VERSION ""

NS_ :

BS_:

BU_: Vector__XXX Vector__XXX ABS ACU ADAS AFS AMP APSB APSM BAT BCM BMS CCM CLU DATC DVRS Drv EPB ESC FR IAU IBU ICSC ICU IEB IFS LDC MCU MDPS MFSW OBC ODS PSM PTGM RR RVM SAS SCM SVM TMU TPMS VCMS VCU WHL YRS
CM_ "FrameID: 0xC7";
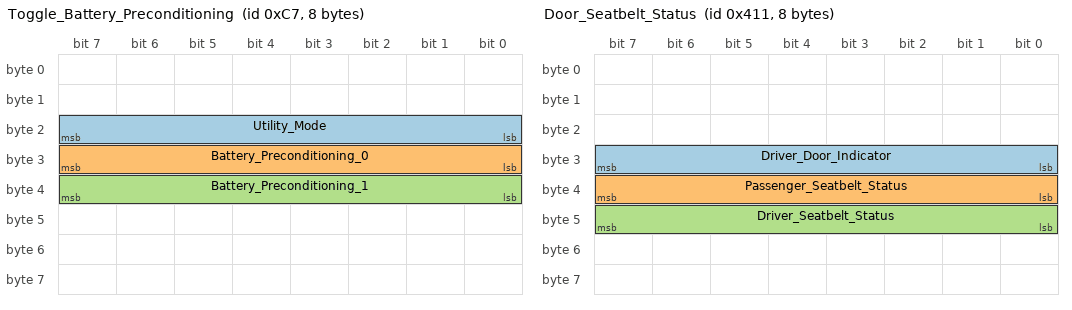
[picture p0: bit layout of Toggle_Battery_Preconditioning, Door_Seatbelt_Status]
BO_ 199 Toggle_Battery_Preconditioning: 8 Vector__XXX
 SG_ Utility_Mode              : 16|8@1+ (1,0) [0|255] "" Vector__XXX
 SG_ Battery_Preconditioning_0 : 24|8@1+ (1,0) [0|255] "" Vector__XXX
 SG_ Battery_Preconditioning_1 : 32|8@1+ (1,0) [0|255] "" Vector__XXX

CM_ "FrameID: 411";
BO_ 1041 Door_Seatbelt_Status: 8 Vector__XXX
 SG_ Driver_Door_Indicator      : 24|8@1+ (1,0) [0|255] "" Vector__XXX
 SG_ Passenger_Seatbelt_Status  : 32|8@1+ (1,0) [0|255] "" Vector__XXX
 SG_ Driver_Seatbelt_Status     : 40|8@1+ (1,0) [0|255] "" Vector__XXX
CM_ BO_ 1041 "a.k.a. ICU ICU_02_200ms in gen5w_hu_rx.dbc";
CM_ SG_ 1041 Driver_Door_Indicator "byte 3. Raw values are 0x51 = 81 (open), 0x50 = 80 (closed) and 0x00 = locked. The VAL_ keys used to be written as the decimal forms of those hex bytes (51/50), which never occur in a capture; they are now the correct integers 81/80. Bit 24 alone is the open flag (see the bit-level Body_Status in ev6-2024.dbc). The two seatbelt signals below are 8-bit wide and therefore also pick up neighbouring bits of bytes 4/5 (0x04 and 0x14 appear), so treat a set bit 36 / 42 as the seatbelt rather than the whole byte.";

CM_ "FrameID: 412";
BO_ 1042 Brake_Pedal_Status: 8 Vector__XXX
 SG_ Brake_Pedal : 48|8@1+ (1,0) [0|255] "" Vector__XXX
CM_ BO_ 1042 "a.k.a. ICU ICU_03_200ms in gen5w_hu_rx.dbc";

CM_ "FrameID: 435";
BO_ 1077 Power_CAN_Status: 8 Vector__XXX
 SG_ Power_State : 56|8@1+ (1,0) [0|255] "" Vector__XXX

CM_ "FrameID: 0x2AD";
BO_ 685 BMS_Precond_Status: 8 Vector__XXX
 SG_ Battery_Precond_State : 8|8@1+ (1,0) [0|255] "" Vector__XXX
CM_ BO_ 685 "a.k.a. VCU VCU_04_100ms_3 in gen5w_hu_rx.dbc";

CM_ "FrameID: 0x418";
BO_ 1048 Steering_Wheel_Heating: 8 Vector__XXX
 SG_ Steering_Wheel_Heating_State : 24|1@1+ (1,0) [0|1] "" Vector__XXX
CM_ BO_ 1048 "a.k.a. ICU ICU_08_200ms in gen5w_hu_rx.dbc";
CM_ SG_ 1048 Steering_Wheel_Heating_State "byte 3 bit 0. Previously modelled at 16|8 (byte 2), which is 0x00 in 100% of every capture on every car (Ioniq 5 5731, Ioniq 6 1916, GV60 1063 frames), so it could only ever read Off. Byte 3 bit 0 is the only bit that tracks the steering-wheel warmer: 0x01 in M-CAN_steering_wheel_warmer_only.csv (10/20 frames), M-CAN_panda_nothing_on_climate_start_both_warmers.csv (60/202) and M-CAN_panda_nothing_on_remote_lock.csv (16/100), and 0x00 in every other capture - including the dedicated left/right seat warmer, climate-on, climate-on-defrost and rear-defrost files, so it is not a generic warmer flag. Byte 5 bit 6 (0x0C -> 0x4C, i.e. bit 45) is the generic one: it turns on with ANY warmer and is a separate candidate signal. The steering-wheel captures are only a few seconds long, so whether byte 3 bit 0 is a latched state or the press event itself is not settled.";
CM_ SG_ 1048 Steering_Wheel_Heating_State "DIFFERENCE ON CCU CARS. This bit-0 encoding is only demonstrated on the Ioniq 5 (NE, ICU CAN hub), and likely works for the EV6 as well. The CCU-hub cars do NOT show it: every Ioniq 6 (1916 frames) and GV60 (1063 frames) sample has byte 3 = 0x40, i.e. bit 6 SET and bit 0 CLEAR, so bit 0 would decode a permanent Off there and the state - if it is reported at all - is carried elsewhere in the byte. Do not apply this signal to a CCU-hub capture (load ioniq6-2024.dbc / gv60-2024.dbc for those).";

CM_ "FrameID: 0x438";
BO_ 1080 RearLeft_Seat_Heating: 8 Vector__XXX
 SG_ RearLeft_Seat_Heating_State :  0|8@1+ (1,0) [0|255] "" Vector__XXX

CM_ "FrameID: 0x448";
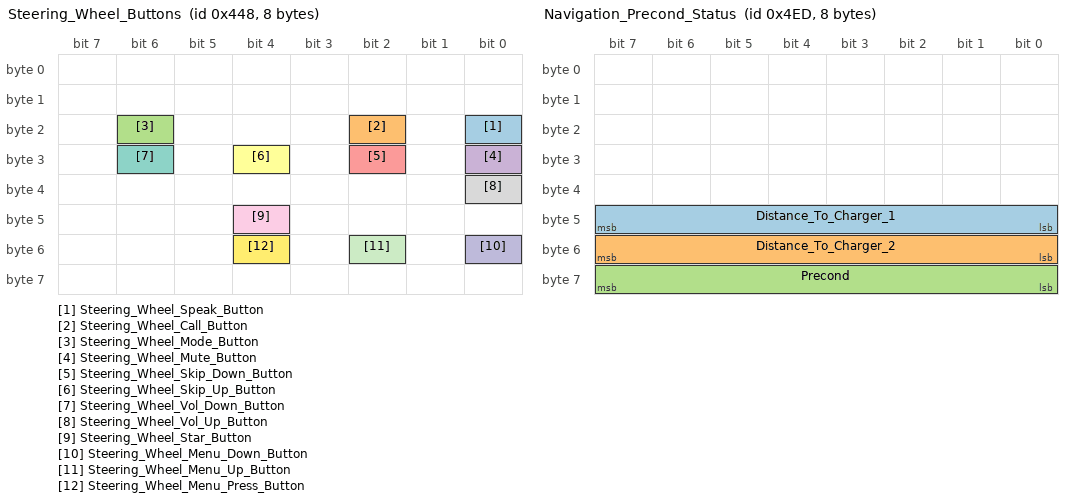
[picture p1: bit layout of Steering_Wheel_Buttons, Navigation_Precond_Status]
BO_ 1096 Steering_Wheel_Buttons: 8 Vector__XXX
 SG_ Steering_Wheel_Speak_Button      : 16|1@1+ (1,0) [0|1] "" Vector__XXX
 SG_ Steering_Wheel_Call_Button       : 18|1@1+ (1,0) [0|1] "" Vector__XXX
 SG_ Steering_Wheel_Mode_Button       : 22|1@1+ (1,0) [0|1] "" Vector__XXX
 SG_ Steering_Wheel_Mute_Button       : 24|1@1+ (1,0) [0|1] "" Vector__XXX
 SG_ Steering_Wheel_Skip_Down_Button  : 26|1@1+ (1,0) [0|1] "" Vector__XXX
 SG_ Steering_Wheel_Skip_Up_Button    : 28|1@1+ (1,0) [0|1] "" Vector__XXX
 SG_ Steering_Wheel_Vol_Down_Button   : 30|1@1+ (1,0) [0|1] "" Vector__XXX
 SG_ Steering_Wheel_Vol_Up_Button     : 32|1@1+ (1,0) [0|1] "" Vector__XXX
 SG_ Steering_Wheel_Star_Button       : 44|1@1+ (1,0) [0|1] "" Vector__XXX
 SG_ Steering_Wheel_Menu_Down_Button  : 48|1@1+ (1,0) [0|1] "" Vector__XXX
 SG_ Steering_Wheel_Menu_Up_Button    : 50|1@1+ (1,0) [0|1] "" Vector__XXX
 SG_ Steering_Wheel_Menu_Press_Button : 52|1@1+ (1,0) [0|1] "" Vector__XXX

CM_ "FrameID: 0x453";
BO_ 1107 RearRight_Seat_Heating: 8 Vector__XXX
 SG_ RearRight_Seat_Heating_State : 0|8@1+ (1,0) [0|255] "" Vector__XXX

CM_ "FrameID: 0x475";
BO_ 1141 Passenger_Seat_Heating: 8 Vector__XXX
 SG_ Passenger_Seat_Heating_State : 0|8@1+ (1,0) [0|255] "" Vector__XXX

CM_ "FrameID: 0x496";
BO_ 1174 Driver_Seat_Heating: 8 Vector__XXX
 SG_ Driver_Seat_Heating_State :    0|8@1+ (1,0) [0|255] "" Vector__XXX
CM_ BO_ 1174 "a.k.a. Drv Drv_SHVU_01_200ms in gen5w_hu_rx.dbc";

CM_ "FrameID: 0x4ED";
BO_ 1261 Navigation_Precond_Status: 8 Vector__XXX
 SG_ Distance_To_Charger_1 : 40|8@1+ (1,0) [0|255] "" Vector__XXX
 SG_ Distance_To_Charger_2 : 48|8@1+ (1,0) [0|255] "" Vector__XXX
 SG_ Precond               : 56|8@1+ (1,0) [0|255] "" Vector__XXX

CM_ "FrameID: 0x0A2";
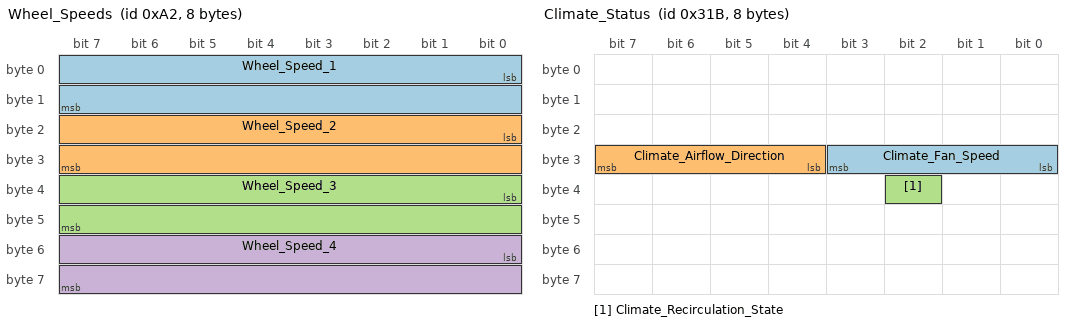
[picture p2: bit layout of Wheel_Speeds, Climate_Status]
BO_ 162 Wheel_Speeds: 8 Vector__XXX
 SG_ Wheel_Speed_1 : 0|16@1+  (0.03125,0) [0|2047.96] "kph" Vector__XXX
 SG_ Wheel_Speed_2 : 16|16@1+ (0.03125,0) [0|2047.96] "kph" Vector__XXX
 SG_ Wheel_Speed_3 : 32|16@1+ (0.03125,0) [0|2047.96] "kph" Vector__XXX
 SG_ Wheel_Speed_4 : 48|16@1+ (0.03125,0) [0|2047.96] "kph" Vector__XXX
CM_ BO_ 162 "a.k.a. WHL WHL_01_10ms_2 in gen5w_hu_rx.dbc";

CM_ "FrameID: 0x1AC";
BO_ 428 Cluster_Info: 8 Vector__XXX
 SG_ Speed_kph : 0|8@1+ (1,0) [0|255] "kph" Vector__XXX
CM_ BO_ 428 "a.k.a. CLU CLU_01_20ms_2 in gen5w_hu_rx.dbc";

CM_ "FrameID: 0x226";
CM_ "Probably wrong: unsigned int, and this byte doesn't change in my logs. --TRH";
BO_ 550 Ambient_Temperature: 8 Vector__XXX
 SG_ Outdoor_Temperature : 24|8@1+ (1,-40) [-40|215] "C" Vector__XXX
CM_ BO_ 550 "a.k.a. CLU CLU_02_100ms_1 in gen5w_hu_rx.dbc";
CM_ SG_ 550 Outdoor_Temperature "byte 3. The bit placement matches the official CLU_OutTempCSta (24|8@1+ (1,-40) [-40|215]) in BO_ 549 CLU_02_100ms of dbcs/dbcs/HMVS4_CAN-FD_DBC_3Gen_R3_rev2.dbc:178, whose VAL_ makes 0..100 = -40..60 C, 101..254 = Reserved and 255 = Invalid. Every Ioniq 5 capture on disk (old/ and current folders, M-CAN and I-CAN) reads 0xFF = 255 = Invalid in this byte, so the -40 offset reports a nonsense 215 C unless 255 is treated as no-data. Bytes 4-7 carry session-stable values of unknown meaning, so a real ambient value may live there instead; unresolved.";
VAL_ 550 Outdoor_Temperature 255 "Invalid" ;

CM_ "FrameID: 0x227";
BO_ 551 Odometer: 8 Vector__XXX
 SG_ Odometer : 8|24@1+ (0.1,0) [0|1677721] "km" Vector__XXX
CM_ BO_ 551 "a.k.a. CLU CLU_02_100ms_2 in gen5w_hu_rx.dbc";

CM_ "FrameID: 0x2FC";
BO_ 764 Battery_Info: 8 Vector__XXX
 SG_ State_Of_Charge : 56|8@1+ (0.5,0) [0|100] "%" Vector__XXX
CM_ BO_ 764 "a.k.a. BMS BMS_02_100ms_2 in gen5w_hu_rx.dbc";

CM_ "FrameID: 0x31B";
BO_ 795 Climate_Status: 8 Vector__XXX
 SG_ Climate_Fan_Speed          : 24|4@1+ (1,0) [0|15] "" Vector__XXX
 SG_ Climate_Airflow_Direction  : 28|4@1+ (1,0) [0|15] "" Vector__XXX
 SG_ Climate_Recirculation_State : 34|1@1+ (1,0) [0|1]  "" Vector__XXX
CM_ BO_ 795 "a.k.a. DATC DATC_31_1000ms_1 in gen5w_hu_rx.dbc";

CM_ BO_ 896 "First three bytes are a rolling counter (byte 0/1 non-monotonic, byte 2 increments with temp step).";
CM_ BO_ 896 "Bytes 0-1 do not appear to be a rolling counter on NA cars: they stay constant per transmitting node/state (3A 85 = HVAC running, AD D7 = HVAC off, A8 33 / C4 50 / 38 B7 / EB F0 / 75 11 / 31 04 = other nodes and transition states), and byte 2 is 00, 01 or FF. Raw 0 is the off state (AD D7 FF 00 00 00 00 01), not a 14 C setpoint. Measured 2026-10/11 on M-CAN and the I-CAN tap: 0x380 adopts a setpoint 1.7 s AFTER byte 1 of 0x39B (D2) carries the same code, with byte 4 of 0x2AC (D5) relaying it on the car bus in between.";
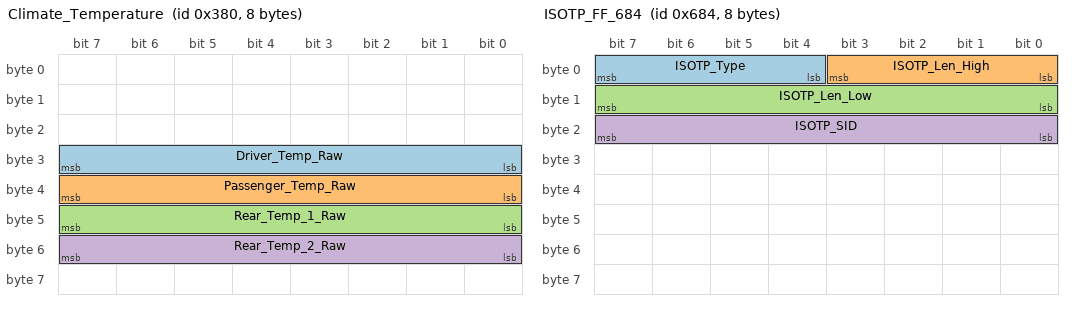
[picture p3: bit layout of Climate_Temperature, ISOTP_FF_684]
BO_ 896 Climate_Temperature: 8 Vector__XXX
 SG_ Driver_Temp_Raw    : 24|8@1+ (0.5,14) [14|32] "C" Vector__XXX
 SG_ Passenger_Temp_Raw : 32|8@1+ (0.5,14) [14|32] "C" Vector__XXX
 SG_ Rear_Temp_1_Raw    : 40|8@1+ (0.5,14) [14|32] "C" Vector__XXX
 SG_ Rear_Temp_2_Raw    : 48|8@1+ (0.5,14) [14|32] "C" Vector__XXX
CM_ BO_ 896 "a.k.a. DATC DATC_03_200ms in gen5w_hu_rx.dbc";

CM_ "FrameID: 0x3AA";
BO_ 938 Charge_Port_Door: 8 Vector__XXX
 SG_ Port_Open : 33|1@1+ (1,0) [0|1] "" Vector__XXX

CM_ "FrameID: 0x414";
BO_ 1044 Trunk_Status: 8 Vector__XXX
 SG_ Trunk_Open : 24|1@1+ (1,0) [0|1] "" Vector__XXX

VAL_ 199  Utility_Mode                 128 "Utility_Mode_Request" 0 "Not_Utility_Mode";
VAL_ 199  Battery_Preconditioning_0    240 "Conditioning_Mode_Enable" 232 "Conditioning_Mode_Disable" 224 "Command_Trailer" 64 "Precond_Start" 16 "Conditioning_Mode_Enable_Alt" 0 "Stop_Phase1_Or_Idle";
VAL_ 199  Battery_Preconditioning_1    7 "Trailer_Operand" 3 "Precond_Start_Operand" 0 "None";
VAL_ 605  Conditioning_Mode_State      128 "Enabled" 64 "Disabled";
VAL_ 1041 Driver_Door_Indicator      81 "Open" 80 "Closed" 0 "Locked";
VAL_ 1041 Passenger_Seatbelt_Status  16 "Fastened" 0 "Unfastened";
VAL_ 1041 Driver_Seatbelt_Status      4 "Fastened" 0 "Unfastened";
VAL_ 1042 Brake_Pedal                 4 "Pressed" 0 "Not_Pressed";
VAL_ 1077 Power_State               255 "Car_Off" 0 "Car_on";
VAL_ 685  Battery_Precond_State        21 "On" 5 "Preparing" 1 "Off" ;
VAL_ 1080 RearLeft_Seat_Heating_State  65 "High" 49 "Low" 17 "Off" ;
VAL_ 1048 Steering_Wheel_Heating_State 1 "On" 0 "Off" ;
VAL_ 1096 Steering_Wheel_Speak_Button      1 "Pressed" 0 "Not_Pressed";
VAL_ 1096 Steering_Wheel_Call_Button       1 "Pressed" 0 "Not_Pressed";
VAL_ 1096 Steering_Wheel_Mode_Button       1 "Pressed" 0 "Not_Pressed";
VAL_ 1096 Steering_Wheel_Mute_Button       1 "Pressed" 0 "Not_Pressed";
VAL_ 1096 Steering_Wheel_Skip_Down_Button  1 "Pressed" 0 "Not_Pressed";
VAL_ 1096 Steering_Wheel_Skip_Up_Button    1 "Pressed" 0 "Not_Pressed";
VAL_ 1096 Steering_Wheel_Vol_Down_Button   1 "Pressed" 0 "Not_Pressed";
VAL_ 1096 Steering_Wheel_Vol_Up_Button     1 "Pressed" 0 "Not_Pressed";
VAL_ 1096 Steering_Wheel_Star_Button       1 "Pressed" 0 "Not_Pressed";
VAL_ 1096 Steering_Wheel_Menu_Down_Button  1 "Pressed" 0 "Not_Pressed";
VAL_ 1096 Steering_Wheel_Menu_Up_Button    1 "Pressed" 0 "Not_Pressed";
VAL_ 1096 Steering_Wheel_Menu_Press_Button 1 "Pressed" 0 "Not_Pressed";
VAL_ 1107 RearRight_Seat_Heating_State 65 "High" 49 "Low" 17 "Off" ;
VAL_ 1141 Passenger_Seat_Heating_State 70 "High" 62 "Medium" 54 "Low" 22 "Off" ;
VAL_ 1174 Driver_Seat_Heating_State    70 "High" 62 "Medium" 54 "Low" 22 "Off" ;
VAL_ 795 Climate_Fan_Speed 0 "Off" 2 "Speed_1" 3 "Speed_2" 4 "Speed_3" 5 "Speed_4" 6 "Speed_5" 7 "Speed_6" 8 "Speed_7" 9 "Speed_8" ;
VAL_ 795 Climate_Airflow_Direction 0 "Auto" 1 "Body" 2 "Body_Legs" 3 "Legs" 4 "Legs_Defog" ;
VAL_ 795 Climate_Recirculation_State 0 "Off" 1 "On" ;
VAL_ 896 Driver_Temp_Raw 0 "Off" ;
VAL_ 896 Passenger_Temp_Raw 0 "Off" ;
VAL_ 896 Rear_Temp_1_Raw 0 "Off" ;
VAL_ 896 Rear_Temp_2_Raw 0 "Off" ;

BO_ 1668 ISOTP_FF_684: 8 Vector__XXX
 SG_ ISOTP_Type        : 4|4@1+  (1,0) [0|15]  ""   Vector__XXX
 SG_ ISOTP_Len_High    : 0|4@1+  (1,0) [0|15]  ""   Vector__XXX
 SG_ ISOTP_Len_Low     : 8|8@1+  (1,0) [0|255] ""   Vector__XXX
 SG_ ISOTP_SID         : 16|8@1+ (1,0) [0|255] ""   Vector__XXX

CM_ BO_ 1668 "ISO-TP First Frame 0x684 → FC from 0x685. TotalLen=(Len_High<<8)|Len_Low";

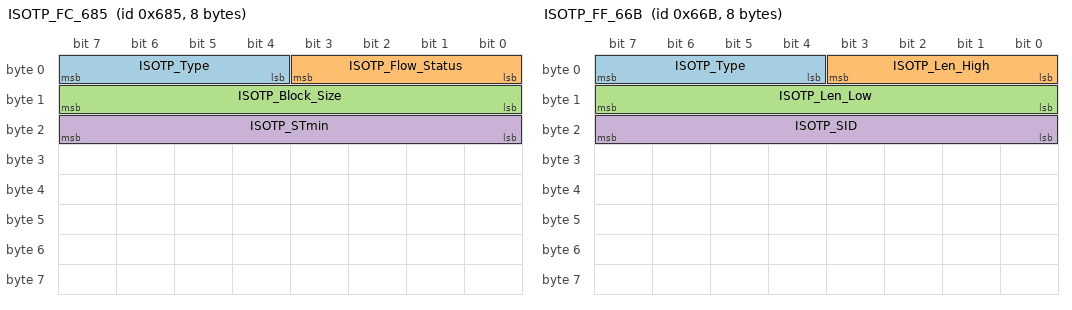
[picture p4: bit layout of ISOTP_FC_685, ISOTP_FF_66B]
BO_ 1669 ISOTP_FC_685: 8 Vector__XXX
 SG_ ISOTP_Type        : 4|4@1+  (1,0) [0|15]  ""   Vector__XXX
 SG_ ISOTP_Flow_Status : 0|4@1+  (1,0) [0|15]  ""   Vector__XXX
 SG_ ISOTP_Block_Size  : 8|8@1+  (1,0) [0|255] ""   Vector__XXX
 SG_ ISOTP_STmin       : 16|8@1+ (1,0) [0|255] "ms" Vector__XXX

CM_ BO_ 1669 "ISO-TP Flow Control 0x685 → responding to 0x684";

BO_ 1643 ISOTP_FF_66B: 8 Vector__XXX
 SG_ ISOTP_Type        : 4|4@1+  (1,0) [0|15]  ""   Vector__XXX
 SG_ ISOTP_Len_High    : 0|4@1+  (1,0) [0|15]  ""   Vector__XXX
 SG_ ISOTP_Len_Low     : 8|8@1+  (1,0) [0|255] ""   Vector__XXX
 SG_ ISOTP_SID         : 16|8@1+ (1,0) [0|255] ""   Vector__XXX

CM_ BO_ 1643 "ISO-TP First Frame 0x66B → FC from 0x69B";

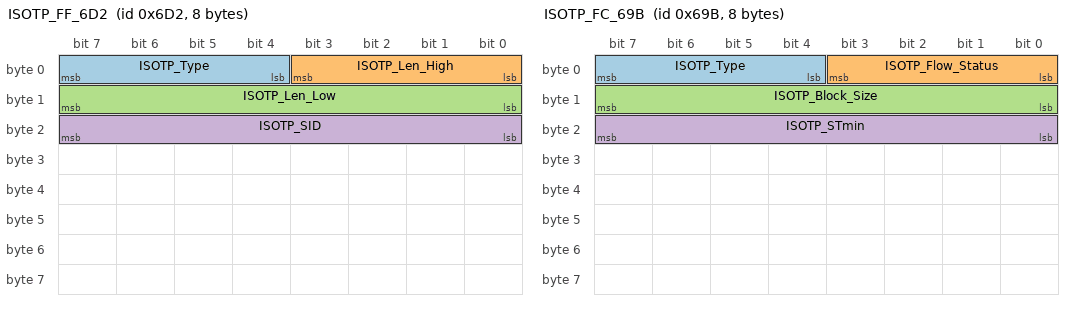
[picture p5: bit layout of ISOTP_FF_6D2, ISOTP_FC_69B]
BO_ 1746 ISOTP_FF_6D2: 8 Vector__XXX
 SG_ ISOTP_Type        : 4|4@1+  (1,0) [0|15]  ""   Vector__XXX
 SG_ ISOTP_Len_High    : 0|4@1+  (1,0) [0|15]  ""   Vector__XXX
 SG_ ISOTP_Len_Low     : 8|8@1+  (1,0) [0|255] ""   Vector__XXX
 SG_ ISOTP_SID         : 16|8@1+ (1,0) [0|255] ""   Vector__XXX

CM_ BO_ 1746 "ISO-TP First Frame 0x6D2 → FC from 0x69B";

BO_ 1691 ISOTP_FC_69B: 8 Vector__XXX
 SG_ ISOTP_Type        : 4|4@1+  (1,0) [0|15]  ""   Vector__XXX
 SG_ ISOTP_Flow_Status : 0|4@1+  (1,0) [0|15]  ""   Vector__XXX
 SG_ ISOTP_Block_Size  : 8|8@1+  (1,0) [0|255] ""   Vector__XXX
 SG_ ISOTP_STmin       : 16|8@1+ (1,0) [0|255] "ms" Vector__XXX

CM_ BO_ 1691 "ISO-TP Flow Control 0x69B → responding to 0x66B and 0x6D2";

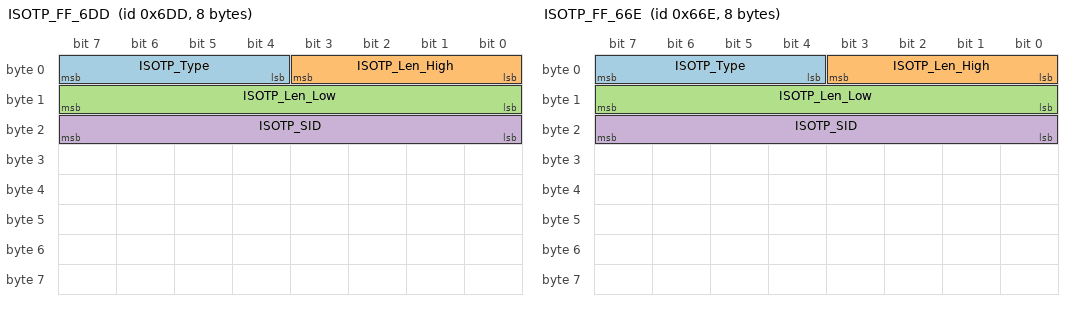
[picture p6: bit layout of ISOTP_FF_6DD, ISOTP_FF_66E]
BO_ 1757 ISOTP_FF_6DD: 8 Vector__XXX
 SG_ ISOTP_Type        : 4|4@1+  (1,0) [0|15]  ""   Vector__XXX
 SG_ ISOTP_Len_High    : 0|4@1+  (1,0) [0|15]  ""   Vector__XXX
 SG_ ISOTP_Len_Low     : 8|8@1+  (1,0) [0|255] ""   Vector__XXX
 SG_ ISOTP_SID         : 16|8@1+ (1,0) [0|255] ""   Vector__XXX

CM_ BO_ 1757 "ISO-TP First Frame 0x6DD → FC from 0x69E";

BO_ 1646 ISOTP_FF_66E: 8 Vector__XXX
 SG_ ISOTP_Type        : 4|4@1+  (1,0) [0|15]  ""   Vector__XXX
 SG_ ISOTP_Len_High    : 0|4@1+  (1,0) [0|15]  ""   Vector__XXX
 SG_ ISOTP_Len_Low     : 8|8@1+  (1,0) [0|255] ""   Vector__XXX
 SG_ ISOTP_SID         : 16|8@1+ (1,0) [0|255] ""   Vector__XXX

CM_ BO_ 1646 "ISO-TP First Frame 0x66E → FC from 0x69E";

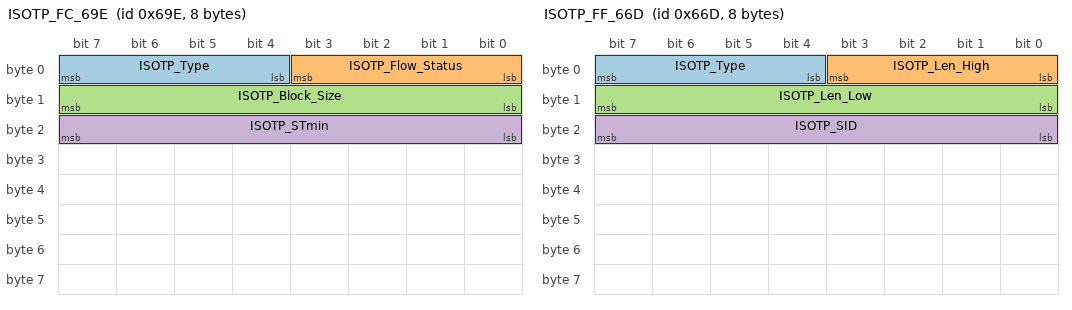
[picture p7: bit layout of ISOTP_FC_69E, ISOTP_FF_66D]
BO_ 1694 ISOTP_FC_69E: 8 Vector__XXX
 SG_ ISOTP_Type        : 4|4@1+  (1,0) [0|15]  ""   Vector__XXX
 SG_ ISOTP_Flow_Status : 0|4@1+  (1,0) [0|15]  ""   Vector__XXX
 SG_ ISOTP_Block_Size  : 8|8@1+  (1,0) [0|255] ""   Vector__XXX
 SG_ ISOTP_STmin       : 16|8@1+ (1,0) [0|255] "ms" Vector__XXX

CM_ BO_ 1694 "ISO-TP Flow Control 0x69E → responding to 0x6DD and 0x66E";

BO_ 1645 ISOTP_FF_66D: 8 Vector__XXX
 SG_ ISOTP_Type        : 4|4@1+  (1,0) [0|15]  ""   Vector__XXX
 SG_ ISOTP_Len_High    : 0|4@1+  (1,0) [0|15]  ""   Vector__XXX
 SG_ ISOTP_Len_Low     : 8|8@1+  (1,0) [0|255] ""   Vector__XXX
 SG_ ISOTP_SID         : 16|8@1+ (1,0) [0|255] ""   Vector__XXX

CM_ BO_ 1645 "ISO-TP First Frame 0x66D → FC from 0x69D";

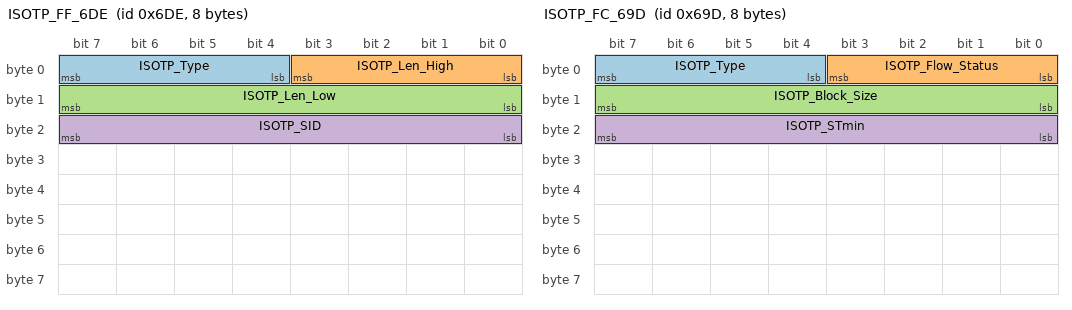
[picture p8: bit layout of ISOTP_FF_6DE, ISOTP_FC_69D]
BO_ 1758 ISOTP_FF_6DE: 8 Vector__XXX
 SG_ ISOTP_Type        : 4|4@1+  (1,0) [0|15]  ""   Vector__XXX
 SG_ ISOTP_Len_High    : 0|4@1+  (1,0) [0|15]  ""   Vector__XXX
 SG_ ISOTP_Len_Low     : 8|8@1+  (1,0) [0|255] ""   Vector__XXX
 SG_ ISOTP_SID         : 16|8@1+ (1,0) [0|255] ""   Vector__XXX

CM_ BO_ 1758 "ISO-TP First Frame 0x6DE → FC from 0x69D";

BO_ 1693 ISOTP_FC_69D: 8 Vector__XXX
 SG_ ISOTP_Type        : 4|4@1+  (1,0) [0|15]  ""   Vector__XXX
 SG_ ISOTP_Flow_Status : 0|4@1+  (1,0) [0|15]  ""   Vector__XXX
 SG_ ISOTP_Block_Size  : 8|8@1+  (1,0) [0|255] ""   Vector__XXX
 SG_ ISOTP_STmin       : 16|8@1+ (1,0) [0|255] "ms" Vector__XXX

CM_ BO_ 1693 "ISO-TP Flow Control 0x69D → responding to 0x66D and 0x6DE";

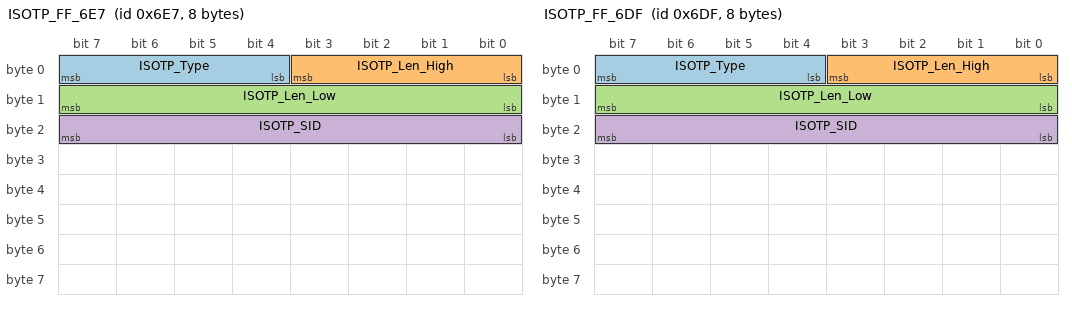
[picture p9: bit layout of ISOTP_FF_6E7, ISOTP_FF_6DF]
BO_ 1767 ISOTP_FF_6E7: 8 Vector__XXX
 SG_ ISOTP_Type        : 4|4@1+  (1,0) [0|15]  ""   Vector__XXX
 SG_ ISOTP_Len_High    : 0|4@1+  (1,0) [0|15]  ""   Vector__XXX
 SG_ ISOTP_Len_Low     : 8|8@1+  (1,0) [0|255] ""   Vector__XXX
 SG_ ISOTP_SID         : 16|8@1+ (1,0) [0|255] ""   Vector__XXX

CM_ BO_ 1767 "ISO-TP First Frame 0x6E7 → FC from 0x6F4";

BO_ 1759 ISOTP_FF_6DF: 8 Vector__XXX
 SG_ ISOTP_Type        : 4|4@1+  (1,0) [0|15]  ""   Vector__XXX
 SG_ ISOTP_Len_High    : 0|4@1+  (1,0) [0|15]  ""   Vector__XXX
 SG_ ISOTP_Len_Low     : 8|8@1+  (1,0) [0|255] ""   Vector__XXX
 SG_ ISOTP_SID         : 16|8@1+ (1,0) [0|255] ""   Vector__XXX

CM_ BO_ 1759 "ISO-TP First Frame 0x6DF → FC from 0x6F4";

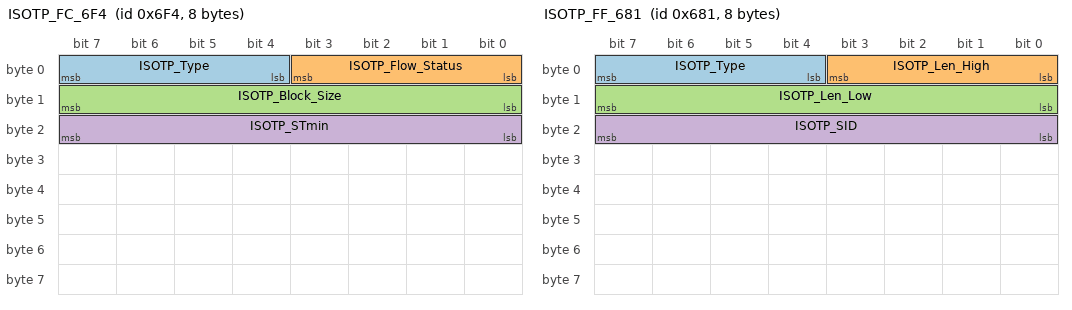
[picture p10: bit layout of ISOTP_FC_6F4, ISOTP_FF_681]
BO_ 1780 ISOTP_FC_6F4: 8 Vector__XXX
 SG_ ISOTP_Type        : 4|4@1+  (1,0) [0|15]  ""   Vector__XXX
 SG_ ISOTP_Flow_Status : 0|4@1+  (1,0) [0|15]  ""   Vector__XXX
 SG_ ISOTP_Block_Size  : 8|8@1+  (1,0) [0|255] ""   Vector__XXX
 SG_ ISOTP_STmin       : 16|8@1+ (1,0) [0|255] "ms" Vector__XXX

CM_ BO_ 1780 "ISO-TP Flow Control 0x6F4 → responding to 0x6E7 and 0x6DF";

BO_ 1665 ISOTP_FF_681: 8 Vector__XXX
 SG_ ISOTP_Type        : 4|4@1+  (1,0) [0|15]  ""   Vector__XXX
 SG_ ISOTP_Len_High    : 0|4@1+  (1,0) [0|15]  ""   Vector__XXX
 SG_ ISOTP_Len_Low     : 8|8@1+  (1,0) [0|255] ""   Vector__XXX
 SG_ ISOTP_SID         : 16|8@1+ (1,0) [0|255] ""   Vector__XXX

CM_ BO_ 1665 "ISO-TP First Frame 0x681 → FC from 0x6AA";

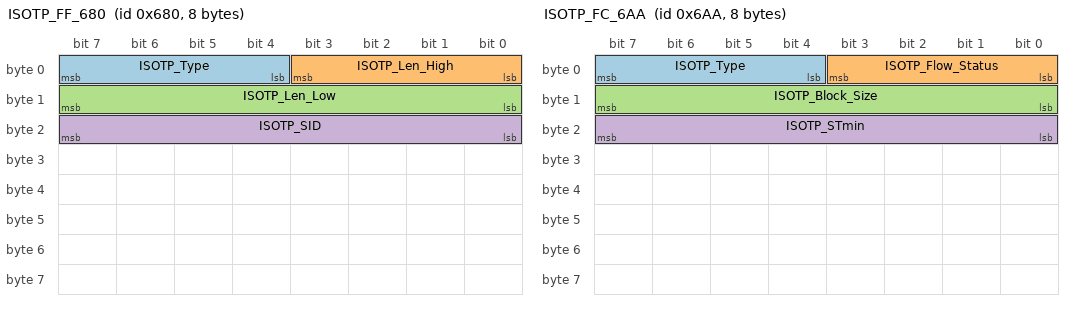
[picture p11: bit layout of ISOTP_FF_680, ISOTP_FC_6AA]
BO_ 1664 ISOTP_FF_680: 8 Vector__XXX
 SG_ ISOTP_Type        : 4|4@1+  (1,0) [0|15]  ""   Vector__XXX
 SG_ ISOTP_Len_High    : 0|4@1+  (1,0) [0|15]  ""   Vector__XXX
 SG_ ISOTP_Len_Low     : 8|8@1+  (1,0) [0|255] ""   Vector__XXX
 SG_ ISOTP_SID         : 16|8@1+ (1,0) [0|255] ""   Vector__XXX

CM_ BO_ 1664 "ISO-TP First Frame 0x680 → FC from 0x6AA";

BO_ 1706 ISOTP_FC_6AA: 8 Vector__XXX
 SG_ ISOTP_Type        : 4|4@1+  (1,0) [0|15]  ""   Vector__XXX
 SG_ ISOTP_Flow_Status : 0|4@1+  (1,0) [0|15]  ""   Vector__XXX
 SG_ ISOTP_Block_Size  : 8|8@1+  (1,0) [0|255] ""   Vector__XXX
 SG_ ISOTP_STmin       : 16|8@1+ (1,0) [0|255] "ms" Vector__XXX

CM_ BO_ 1706 "ISO-TP Flow Control 0x6AA → responding to 0x680 and 0x681";

VAL_ 1668 ISOTP_Type 0 "SingleFrame" 1 "FirstFrame" 2 "ConsecFrame" 3 "FlowCtrl";
VAL_ 1643 ISOTP_Type 0 "SingleFrame" 1 "FirstFrame" 2 "ConsecFrame" 3 "FlowCtrl";
VAL_ 1746 ISOTP_Type 0 "SingleFrame" 1 "FirstFrame" 2 "ConsecFrame" 3 "FlowCtrl";
VAL_ 1757 ISOTP_Type 0 "SingleFrame" 1 "FirstFrame" 2 "ConsecFrame" 3 "FlowCtrl";
VAL_ 1646 ISOTP_Type 0 "SingleFrame" 1 "FirstFrame" 2 "ConsecFrame" 3 "FlowCtrl";
VAL_ 1645 ISOTP_Type 0 "SingleFrame" 1 "FirstFrame" 2 "ConsecFrame" 3 "FlowCtrl";
VAL_ 1758 ISOTP_Type 0 "SingleFrame" 1 "FirstFrame" 2 "ConsecFrame" 3 "FlowCtrl";
VAL_ 1767 ISOTP_Type 0 "SingleFrame" 1 "FirstFrame" 2 "ConsecFrame" 3 "FlowCtrl";
VAL_ 1759 ISOTP_Type 0 "SingleFrame" 1 "FirstFrame" 2 "ConsecFrame" 3 "FlowCtrl";
VAL_ 1665 ISOTP_Type 0 "SingleFrame" 1 "FirstFrame" 2 "ConsecFrame" 3 "FlowCtrl";
VAL_ 1664 ISOTP_Type 0 "SingleFrame" 1 "FirstFrame" 2 "ConsecFrame" 3 "FlowCtrl";
VAL_ 1669 ISOTP_Type 0 "SingleFrame" 1 "FirstFrame" 2 "ConsecFrame" 3 "FlowCtrl";
VAL_ 1691 ISOTP_Type 0 "SingleFrame" 1 "FirstFrame" 2 "ConsecFrame" 3 "FlowCtrl";
VAL_ 1694 ISOTP_Type 0 "SingleFrame" 1 "FirstFrame" 2 "ConsecFrame" 3 "FlowCtrl";
VAL_ 1693 ISOTP_Type 0 "SingleFrame" 1 "FirstFrame" 2 "ConsecFrame" 3 "FlowCtrl";
VAL_ 1780 ISOTP_Type 0 "SingleFrame" 1 "FirstFrame" 2 "ConsecFrame" 3 "FlowCtrl";
VAL_ 1706 ISOTP_Type 0 "SingleFrame" 1 "FirstFrame" 2 "ConsecFrame" 3 "FlowCtrl";
VAL_ 1669 ISOTP_Flow_Status 0 "ContinueToSend" 1 "Wait" 2 "Overflow";
VAL_ 1691 ISOTP_Flow_Status 0 "ContinueToSend" 1 "Wait" 2 "Overflow";
VAL_ 1694 ISOTP_Flow_Status 0 "ContinueToSend" 1 "Wait" 2 "Overflow";
VAL_ 1693 ISOTP_Flow_Status 0 "ContinueToSend" 1 "Wait" 2 "Overflow";
VAL_ 1780 ISOTP_Flow_Status 0 "ContinueToSend" 1 "Wait" 2 "Overflow";
VAL_ 1706 ISOTP_Flow_Status 0 "ContinueToSend" 1 "Wait" 2 "Overflow";

BO_ 996 VIN_Broadcast: 8 Vector__XXX
 SG_ VIN_Frame M  :  0|8@1+ (1,0) [0|255] "" Vector__XXX
 SG_ VIN_C01 m42  : 56|8@1+ (1,0) [0|255] "" Vector__XXX
 SG_ VIN_C02 m42  : 48|8@1+ (1,0) [0|255] "" Vector__XXX
 SG_ VIN_C03 m42  : 40|8@1+ (1,0) [0|255] "" Vector__XXX
 SG_ VIN_C04 m42  : 32|8@1+ (1,0) [0|255] "" Vector__XXX
 SG_ VIN_C05 m42  : 24|8@1+ (1,0) [0|255] "" Vector__XXX
 SG_ VIN_C06 m42  : 16|8@1+ (1,0) [0|255] "" Vector__XXX
 SG_ VIN_C07 m42  :  8|8@1+ (1,0) [0|255] "" Vector__XXX
 SG_ VIN_C08 m74  : 56|8@1+ (1,0) [0|255] "" Vector__XXX
 SG_ VIN_C09 m74  : 48|8@1+ (1,0) [0|255] "" Vector__XXX
 SG_ VIN_C10 m74  : 40|8@1+ (1,0) [0|255] "" Vector__XXX
 SG_ VIN_C11 m74  : 32|8@1+ (1,0) [0|255] "" Vector__XXX
 SG_ VIN_C12 m74  : 24|8@1+ (1,0) [0|255] "" Vector__XXX
 SG_ VIN_C13 m74  : 16|8@1+ (1,0) [0|255] "" Vector__XXX
 SG_ VIN_C14 m74  :  8|8@1+ (1,0) [0|255] "" Vector__XXX
 SG_ VIN_C15 m106 : 56|8@1+ (1,0) [0|255] "" Vector__XXX
 SG_ VIN_C16 m106 : 48|8@1+ (1,0) [0|255] "" Vector__XXX
 SG_ VIN_C17 m106 : 40|8@1+ (1,0) [0|255] "" Vector__XXX

CM_ BO_ 996 "0x3E4. The VIN embedding here appears to be region-specific and does not work on North American cars. Modelled as a multiplexed VIN broadcast: VIN_Frame mux 42/74/106 with VIN_C01..C17, chars in reverse byte order (byte7=VIN[1], byte6=VIN[2]...), mux 0x2A = VIN[1-7], 0x4A = VIN[8-14], 0x6A = VIN[15-17].";

VAL_ 996 VIN_Frame 42 "VIN_chars_01_07" 74 "VIN_chars_08_14" 106 "VIN_chars_15_17";

CM_ BO_ 199 "Low level BMU control (0x0C7). Every command is 3 frames at 25 Hz followed by a 3-frame commit. Utility mode: D3=80 E0 07 then D3=00 E0 07. Conditioning mode enable: D4=F0 07 then D4=E0 07; disable: D4=E8 07 then D4=E0 07 (conditioning_mode_check.md, utility_mode.md). Preconditioning start: D4=40 03 then D4=E0 07; stop: D4=00 00 then D4=E0 07. A D4=10 00 pair also enabled conditioning mode in the 2026-09-07 MITM capture but is undocumented.";
CM_ SG_ 199 Utility_Mode "byte 2 (D3): 0x80 = utility-mode request (paired with D4=E0 D5=07); 0x00 = commit phase / not utility mode";
CM_ SG_ 199 Battery_Preconditioning_0 "byte 3 (D4) opcode: 0x00 stop phase 1, 0x10 undocumented conditioning-mode enable, 0x40 preconditioning start, 0xE0 command trailer, 0xE8 conditioning-mode disable, 0xF0 conditioning-mode enable";
CM_ SG_ 199 Battery_Preconditioning_1 "byte 4 (D5) operand: 0x00 with D4=00/10, 0x03 preconditioning start, 0x07 utility mode / conditioning enable / disable and the 0xE0 command trailer";
CM_ BO_ 685 "BMS_Precond_Status (0x2AD), Ioniq 5 / EV6. Byte 1 state: Ioniq 5 0x01 idle / 0x05 starting / 0x15 started; EV6 0x41 / 0x45 / 0x55. Ioniq 6 uses the extended ID 0x0A82AA03 instead.";
CM_ BO_ 1261 "Navigation_Precond_Status (0x4ED): navigation distance to charger and precondition flag.";
CM_ BO_ 1096 "Steering-wheel buttons (0x448): star, mode, speak, call, volume, skip, OK buttons.";

BO_ 56 Power_Status: 8 Vector__XXX
	SG_ Power_Status_Ready : 0|4@1+ (1,0) [0|0] "" Vector__XXX
CM_ BO_ 56 "a.k.a. VCU VCU_01_10ms_3 in gen5w_hu_rx.dbc";

CM_ BO_ 56 "POWER_STATUS (0x038) power/READY frame. LS nibble of byte 0: 0x01 = awake but off (with some lag), 0x04 = READY.";
CM_ SG_ 56 Power_Status_Ready "LS nibble of byte 0";

VAL_ 56 Power_Status_Ready 1 "Awake_Not_Ready" 4 "Ready" ;

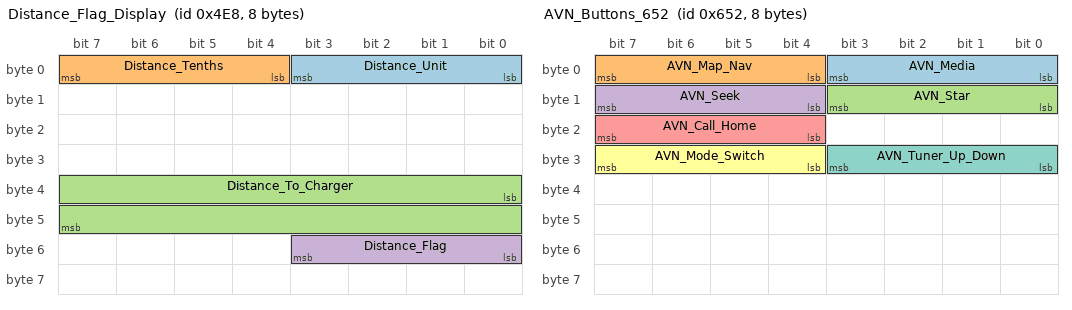
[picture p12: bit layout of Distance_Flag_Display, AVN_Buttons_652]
BO_ 1256 Distance_Flag_Display: 8 Vector__XXX
	SG_ Distance_Unit : 0|4@1+ (1,0) [0|0] "" Vector__XXX
	SG_ Distance_Tenths : 4|4@1+ (1,0) [0|0] "" Vector__XXX
	SG_ Distance_To_Charger : 32|16@1+ (1,0) [0|0] "" Vector__XXX
	SG_ Distance_Flag : 48|4@1+ (1,0) [0|0] "" Vector__XXX

CM_ BO_ 1256 "Distance/flag display (0x4E8): byte0 = tenths<<4 | unit; bytes 4-5 = uint16 distance (LE); byte 6 LS nibble = flag. 0xFFFF distance hides the number.";
CM_ SG_ 1256 Distance_Unit "byte 0 LS nibble";
CM_ SG_ 1256 Distance_Tenths "byte 0 MS nibble";
CM_ SG_ 1256 Distance_To_Charger "bytes 4-5, uint16 LE";
CM_ SG_ 1256 Distance_Flag "byte 6 LS nibble";

VAL_ 1256 Distance_Unit 0 "M" 1 "KM" 2 "MI" 3 "FT" 4 "YD" ;
VAL_ 1256 Distance_Flag 0 "Destination" 1 "Blue 1" 2 "Blue 2" 3 "Blue 3" 4 "Blue 4" 15 "None" ;

BO_ 1228 Precond_Countdown_Flag: 8 Vector__XXX
	SG_ Precond_Countdown : 0|8@1+ (1,0) [0|0] "" Vector__XXX

CM_ SG_ 1228 Precond_Countdown "byte 0";

BO_ 338 Battery_Temperature: 8 Vector__XXX
	SG_ Battery_Temperature_Min : 0|8@1- (1,0) [0|0] "" Vector__XXX
	SG_ Battery_Temperature_Max : 8|8@1- (1,0) [0|0] "" Vector__XXX
CM_ BO_ 338 "a.k.a. BMS BMS_10_100ms_2 in gen5w_hu_rx.dbc";

CM_ BO_ 338 "Battery temperature (0x152): data[0] = min cell temp, data[1] = max cell temp (int8, deg C).";
CM_ SG_ 338 Battery_Temperature_Min "byte 0, signed deg C";
CM_ SG_ 338 Battery_Temperature_Max "byte 1, signed deg C";

BO_ 1617 AVN_Buttons_651: 8 Vector__XXX
	SG_ AVN_Vol_In : 12|4@1+ (1,0) [0|0] "" Vector__XXX
	SG_ AVN_Tuner_In : 28|4@1+ (1,0) [0|0] "" Vector__XXX

CM_ BO_ 1617 "AVN (head unit) button events (0x651); event frames sent only on press/release. VOL_IN = byte 1 MS nibble, TUNER_IN = byte 3 MS nibble.";
CM_ SG_ 1617 AVN_Vol_In "byte 1 MS nibble (mask 0xF0)";
CM_ SG_ 1617 AVN_Tuner_In "byte 3 MS nibble (mask 0xF0)";

VAL_ 1617 AVN_Vol_In 0 "Release" 3 "Release" 4 "Press" 7 "Press" ;
VAL_ 1617 AVN_Tuner_In 0 "Release" 3 "Release" 4 "Press" 7 "Press" ;

BO_ 1618 AVN_Buttons_652: 8 Vector__XXX
	SG_ AVN_Media : 0|4@1+ (1,0) [0|0] "" Vector__XXX
	SG_ AVN_Map_Nav : 4|4@1+ (1,0) [0|0] "" Vector__XXX
	SG_ AVN_Star : 8|4@1+ (1,0) [0|0] "" Vector__XXX
	SG_ AVN_Seek : 12|4@1+ (1,0) [0|0] "" Vector__XXX
	SG_ AVN_Call_Home : 20|4@1+ (1,0) [0|0] "" Vector__XXX
	SG_ AVN_Mode_Switch : 28|4@1+ (1,0) [0|0] "" Vector__XXX
	SG_ AVN_Tuner_Up_Down : 24|4@1+ (1,0) [0|0] "" Vector__XXX

CM_ BO_ 1618 "AVN (head unit) button events (0x652). Per-byte nibble encoding: D1(byte0) MS=MAP/NAV LS=MEDIA; D2(byte1) MS=SEEK LS=STAR; D3(byte2) MS=CALL/HOME; D4(byte3) MS=MODE LS=TUNER UP/DOWN. Brute-force source: 0x652 button list. NOTE: Seek/Call/Home/Mode signals are EV6-specific per fluxer notes; presence on Ioniq 5 unconfirmed.";
CM_ SG_ 1618 AVN_Media "byte 0 LS nibble (mask 0x0F). 1=Media, 4=Radio (start radio, unconfirmed per fluxer notes)";
CM_ SG_ 1618 AVN_Map_Nav "byte 0 MS nibble (mask 0xF0). 1=Nav, 4=Map";
CM_ SG_ 1618 AVN_Star "byte 1 LS nibble (mask 0x0F). 4=Star";
CM_ SG_ 1618 AVN_Seek "byte 1 MS nibble (mask 0xF0). 1=Seek Right, 4=Seek Left (EV6 confirmed, assumed platform)";
CM_ SG_ 1618 AVN_Call_Home "byte 2 MS nibble (mask 0xF0). 1=Call, 4=Home (unconfirmed)";
CM_ SG_ 1618 AVN_Mode_Switch "byte 3 MS nibble (mask 0xF0). Transitions: 5F->4F->7F->FF = climate-to-media, BF->FF = media-to-climate (EV6 observed, assumed platform)";
CM_ SG_ 1618 AVN_Tuner_Up_Down "byte 3 LS nibble (mask 0x0F). 1=Down, 4=Up";

VAL_ 1618 AVN_Media 0 "Release" 1 "Press" 4 "Radio" 12 "Release" 13 "Press" ;
VAL_ 1618 AVN_Map_Nav 0 "Release" 1 "Nav Press" 3 "Release" 4 "Map Press" 7 "Map Press" 12 "Release" 13 "Nav Press" ;
VAL_ 1618 AVN_Star 0 "Release" 3 "Release" 4 "Press" 7 "Press" ;
VAL_ 1618 AVN_Seek 0 "Release" 1 "Seek Right" 4 "Seek Left" 3 "Release" 12 "Release" ;
VAL_ 1618 AVN_Call_Home 0 "Release" 1 "Call" 4 "Home" ;
VAL_ 1618 AVN_Mode_Switch 4 "Mode_Media_?" 5 "Climate_To_Media_Step" 7 "Mode_Change_Complete_?" 11 "Media_To_Climate_Request" 15 "Idle" ;
VAL_ 1618 AVN_Tuner_Up_Down 0 "Release" 1 "Down Press" 3 "Release" 4 "Up Press" 7 "Up Press" 12 "Release" 13 "Down Press" ;

BO_ 57 Power_State_Aux: 8 Vector__XXX
	SG_ Power_State_Aux_Raw : 0|8@1+ (1,0) [0|255] "" Vector__XXX
CM_ BO_ 57 "a.k.a. VCU VCU_01_10ms_4 in gen5w_hu_rx.dbc";

CM_ BO_ 57 "Power_State_Aux (0x039): byte 0 value 0x09 = power-up transition (fires 4x when going up). 0x05/0x07 = possible door wake bursts. Runs at 20Hz when car is awake.";
CM_ SG_ 57 Power_State_Aux_Raw "byte 0 raw";

VAL_ 57 Power_State_Aux_Raw 5 "Door_Wake_Burst_05" 7 "Door_Wake_Burst_07" 9 "Powering_Up" ;

BO_ 782 Charging_Power: 8 Vector__XXX
	SG_ Charging_Power_kW : 48|8@1+ (1,0) [0|255] "kW" Vector__XXX
CM_ BO_ 782 "a.k.a. VCMS VCMS_02_100ms_4 in gen5w_hu_rx.dbc";

CM_ BO_ 782 "Charging_Power (0x30E): byte 6 = charging power in kW.";

BO_ 1053 Climate_Driver_Only_Control: 8 Vector__XXX
	SG_ Driver_Only_Request : 32|8@1+ (1,0) [0|255] "" Vector__XXX

CM_ BO_ 1053 "Climate_Driver_Only_Control (0x41D): byte 4 (D5) toggles 0x0D->0x0F for on, 0x0C->0x0F for off. Heat toggle also on this frame (unspecified bits). Head-unit-generated climate control.";
CM_ SG_ 1053 Driver_Only_Request "byte 4 (D5): 0x0C=Driver_Only_Off, 0x0D=Driver_Only_On, 0x0F=Applied";

VAL_ 1053 Driver_Only_Request 12 "Driver_Only_Off" 13 "Driver_Only_On" 15 "Applied" ;

BO_ 1183 Climate_Temp_Control: 8 Vector__XXX
	SG_ Temp_Control : 0|8@1+ (1,0) [0|255] "" Vector__XXX

CM_ BO_ 1183 "Climate_Temp_Control (0x49F): byte 0 (D1). 0x70->0xF0 = Driver Temp Up, 0xB0->0xF0 = Driver Down, 0xD0->0xF0 = Passenger Up, 0xE0->0xF0 = Passenger Down. 0xF0 = released/idle. Also contains AC toggle and auto toggle (unspecified bits). Head-unit-generated.";
CM_ SG_ 1183 Temp_Control "byte 0 (D1): high nibble encodes direction, F0=idle";

VAL_ 1183 Temp_Control 112 "Driver_Temp_Up" 176 "Driver_Temp_Down" 208 "Passenger_Temp_Up" 224 "Passenger_Temp_Down" 240 "Idle" ;

BO_ 1184 Climate_Sync_Control: 8 Vector__XXX
	SG_ Sync_Request : 24|8@1+ (1,0) [0|255] "" Vector__XXX

CM_ BO_ 1184 "Climate_Sync_Control (0x4A0): byte 3 (D4). 0x0B->0x0F = Sync On, 0x07->0x0F = Sync Off. 0x0F = applied/idle.";
CM_ SG_ 1184 Sync_Request "byte 3 (D4): 0x07=Sync_Off, 0x0B=Sync_On, 0x0F=Applied";

VAL_ 1184 Sync_Request 7 "Sync_Off" 11 "Sync_On" 15 "Applied" ;

CM_ "FrameID: 0x4F1 (Remote_Session_Status) - head-unit 1 Hz status frame; byte 1 carries the remote-session state.";
BO_ 1265 Remote_Session_Status: 8 Vector__XXX
 SG_ Remote_Session : 8|8@1+ (1,0) [0|255] "" Vector__XXX

CM_ BO_ 1265 "Remote_Session_Status (0x4F1): 1 Hz head-unit frame, bytes 2-7 constant 00 in every capture. Byte 1 = 0xF0 when the head unit is in its long-idle state, 0xC0 when awake and idle, 0xD0 while a remote action is in flight. The C0->D0 edge is a 3-frame burst at 40 ms, then holds at 1 Hz for 7-12 s, then closes with a 3-frame C0 burst; every 0x4A2 burst re-opens or extends the window. A cloud start from a sleeping car is F0 -> C0 (3.0 s) -> D0, and only the D0 edge carries the 0x4A2 session-open burst, so D0 is a window, not a latch. Not modelled by any other DBC.";
CM_ SG_ 1265 Remote_Session "byte 1: 0xF0 = asleep/idle, 0xC0 = awake, 0xD0 = remote window open";

VAL_ 1265 Remote_Session 192 "Awake" 208 "Remote_Window" 240 "Asleep_Idle" ;

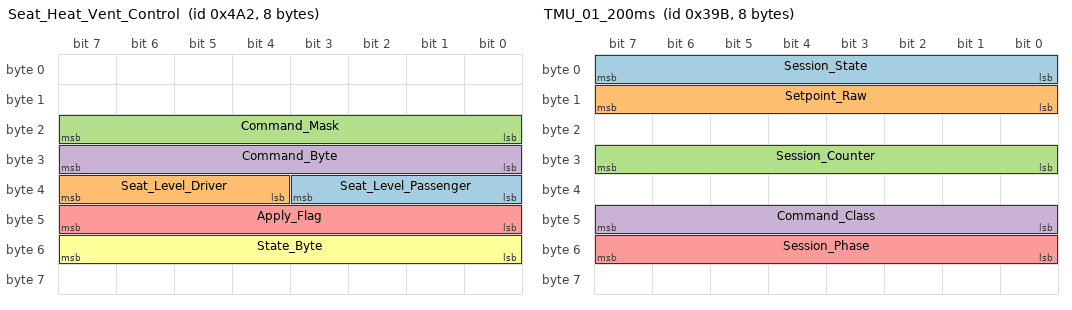
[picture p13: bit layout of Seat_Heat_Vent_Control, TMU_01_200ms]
BO_ 1186 Seat_Heat_Vent_Control: 8 Vector__XXX
	SG_ Seat_Level_Passenger : 32|4@1+ (1,0) [0|15] "" Vector__XXX
	SG_ Seat_Level_Driver    : 36|4@1+ (1,0) [0|15] "" Vector__XXX
	SG_ Command_Mask : 16|8@1+ (1,0) [0|255] "" Vector__XXX
	SG_ Command_Byte : 24|8@1+ (1,0) [0|255] "" Vector__XXX
	SG_ Apply_Flag : 40|8@1+ (1,0) [0|255] "" Vector__XXX
	SG_ State_Byte : 48|8@1+ (1,0) [0|255] "" Vector__XXX

CM_ BO_ 1186 "Seat_Heat_Vent_Control (0x4A2): D5 (byte 4). High nibble = driver, low nibble = passenger. F = idle/no-change. Ioniq5 values: 8=High, 7=Medium, 6=Low, 2=Off.";
CM_ BO_ 1186 "Seat_Heat_Vent_Control (0x4A2) is really the head unit's generic remote-comfort command. Bytes 0/1 (D1/D2) are always 00 00. Byte 2 (D3) = command mask; byte 3 (D4) = command byte, bit 7 = request->apply commit; byte 4 (D5) = seat levels (high nibble driver, low nibble passenger: 2=Off, 6=Low, 7=Medium, 8=High, F=idle/no-change), which is why the apply phase's FF FF reads as Idle; byte 5 (D6) = 0xFF only in the apply phase; byte 6 (D7) = function/state byte. Every phase is 3 frames at ~25 Hz and the second phase 120 ms later repeats the mask with byte 2 = 0xFF ('apply'). Capture notes number the bytes D0..D7 (0-based).";
CM_ SG_ 1186 Command_Mask "byte 2 (D3): 0x0F = climate start, 0x7F = climate + rear/side defrost, 0xDF = climate + seat warmers, 0xF3 = lock/unlock or session-open, 0xFF = apply/refresh";
CM_ SG_ 1186 Command_Byte "byte 3 (D4): bit 7 set in the apply phase (0x43->0xC3). 0x03 in local presses, 0x43/0xC3 in every 2026-11-04 cloud capture; bit 6 is unexplained.";
CM_ SG_ 1186 Apply_Flag "byte 5 (D6): 0xFF in the apply burst, 0x00 in the request burst";
CM_ SG_ 1186 State_Byte "byte 6 (D7): 0x00 plain climate, 0xF0 with front defrost / steering-wheel warmer (request and apply), 0xC0 then 0x40 = lock, 0xD0 then 0xF0 = unlock";

VAL_ 1186 Command_Mask 15 "Climate_Start" 127 "Climate_Rear_Side_Defrost" 223 "Climate_Warmers" 243 "Lock_Unlock_or_Session_Open" 255 "Apply_or_Refresh" ;
VAL_ 1186 Command_Byte 3 "Local_Request" 67 "Cloud_Request" 195 "Cloud_Apply" ;

CM_ SG_ 1186 Seat_Level_Driver "byte 4 high nibble (mask 0xF0): 2=Off, 6=Low, 7=Med, 8=High, F=Idle";
CM_ SG_ 1186 Seat_Level_Passenger "byte 4 low nibble (mask 0x0F): same codes as driver, F=Idle";

VAL_ 1186 Seat_Level_Driver 2 "Off" 6 "Low" 7 "Medium" 8 "High" 15 "Idle" ;
VAL_ 1186 Seat_Level_Passenger 2 "Off" 6 "Low" 7 "Medium" 8 "High" 15 "Idle" ;

CM_ "FrameID: 0x4C5 (Charge_Limit_Control). AC limit in byte 4 (D5), DC limit in byte 5 (D6); raw code = 2x percent (0x64=50, 0x8C=70, 0xA0=80, 0xB4=90, 0xC8=100), 0xFF = off. Same frame/signals as ev6-2024.dbc. MITM-injected on the M-CAN by wicant-i-precondition car_settings.c. The frames below (0x1F9/0x25D/0x329/0x333/0x334) are car-side charge-limit status echoes (~200 ms periodic): their bytes track the injected AC/DC values in the reply run (M-CAN_MITM_send_AC_DC_settings_80-90-80-90_AC_then_same_DC.csv) and stay put in the no-reply run (M-CAN_MITM_send_AC_DC_settings_no_reply.csv), so they are usable as an apply-acknowledgement.";
CM_ BO_ 1221 "Charge_Limit_Control (0x4C5): byte 4 = AC charge limit %, byte 5 = DC charge limit %, factor 0.5. See also ev6-2024.dbc.";
CM_ SG_ 1221 AC_Charge_Limit "byte 4 (D5)";
CM_ SG_ 1221 DC_Charge_Limit "byte 5 (D6)";
BO_ 1221 Charge_Limit_Control: 8 Vector__XXX
 SG_ AC_Charge_Limit : 32|8@1+ (0.5,0) [0|100] "%" Vector__XXX
 SG_ DC_Charge_Limit : 40|8@1+ (0.5,0) [0|100] "%" Vector__XXX

CM_ "FrameID: 0x1F9";
CM_ BO_ 505 "Car-side charge-limit status echo (~200 ms periodic). Byte 2 (D3) = AC charge limit %, byte 3 (D4) = DC charge limit % (factor 0.5). Reply-run baseline (no active 0x4C5) is D3=D4=0xB4 (90%); an injected AC 80% flips D3 to 0xA0 and an injected DC 80% flips D4 to 0xA0, both reverting when the 0x4C5 goes passive. The no-reply run's AC 80%/100% injections leave D3/D4 untouched (only a one-off 100->90 baseline step at ~t=25.1 s). Other bytes not mapped.";
CM_ SG_ 505 AC_Charge_Limit "byte 2 (D3)";
CM_ SG_ 505 DC_Charge_Limit "byte 3 (D4)";
BO_ 505 Charge_Limit_Status_1F9: 8 Vector__XXX
 SG_ AC_Charge_Limit : 16|8@1+ (0.5,0) [0|100] "%" Vector__XXX
 SG_ DC_Charge_Limit : 24|8@1+ (0.5,0) [0|100] "%" Vector__XXX
CM_ BO_ 505 "a.k.a. BMS BMS_08_100ms_4 in gen5w_hu_rx.dbc";

CM_ "FrameID: 0x25D";
CM_ BO_ 605 "Car-side DC charge-limit status echo (~200 ms periodic). Byte 1 (D2) = DC charge limit %, factor 0.5 (0xA0=80%, 0xB4=90%). Mirrors 0x4C5 byte 5 (D6, DC) when accepted (reply run); it does not carry the AC limit and is untouched by the no-reply run's AC 80%/100% injections.";
CM_ SG_ 605 DC_Charge_Limit "byte 1 (D2)";
CM_ SG_ 605 Conditioning_Mode_State "byte 5 (D6): latched battery conditioning mode, 0x80 = enabled / 0x40 = disabled. Flips within one frame period of a 0x0C7 D4=F0 (enable) or D4=E8 (disable) burst on bus 1; 7/7 commands in the 2026-09-07 MITM captures.";
BO_ 605 Charge_Limit_DC_Status_25D: 8 Vector__XXX
 SG_ DC_Charge_Limit : 8|8@1+ (0.5,0) [0|100] "%" Vector__XXX
 SG_ Conditioning_Mode_State : 40|8@1+ (1,0) [0|255] "" Vector__XXX
CM_ BO_ 605 "a.k.a. BMS BMS_04_100ms_3 in gen5w_hu_rx.dbc";

CM_ "FrameID: 0x329";
CM_ BO_ 809 "Car-side AC charge-limit status echo (~200 ms periodic). Byte 0 (D1) = AC charge limit %, factor 0.5 (0xA0=80%, 0xB4=90%). Mirrors 0x4C5 byte 4 (D5, AC) when accepted (reply run); unchanged by the no-reply run's AC injections. Byte 1 toggles 0x90/0xC8 independently (not mapped).";
CM_ SG_ 809 AC_Charge_Limit "byte 0 (D1)";
BO_ 809 Charge_Limit_AC_Status_329: 8 Vector__XXX
 SG_ AC_Charge_Limit : 0|8@1+ (0.5,0) [0|100] "%" Vector__XXX
CM_ BO_ 809 "a.k.a. BMS BMS_06_100ms_4 in gen5w_hu_rx.dbc";

CM_ "FrameID: 0x333";
CM_ BO_ 819 "Car-side AC charge-limit status echo (~200 ms periodic). Byte 7 (D8) = AC charge limit %, factor 0.5 (0xA0=80%, 0xB4=90%). Mirrors 0x4C5 byte 4 (D5, AC) when accepted (reply run); unchanged by the no-reply run's AC injections.";
CM_ SG_ 819 AC_Charge_Limit "byte 7 (D8)";
BO_ 819 Charge_Limit_AC_Status_333: 8 Vector__XXX
 SG_ AC_Charge_Limit : 56|8@1+ (0.5,0) [0|100] "%" Vector__XXX
CM_ BO_ 819 "a.k.a. BMS BMS_05_100ms_3 in gen5w_hu_rx.dbc";

CM_ "FrameID: 0x334";
CM_ BO_ 820 "Car-side charge-limit status echo (~200 ms periodic). Byte 0 (D1) = DC charge limit %, factor 0.5 (0xA0=80%, 0xB4=90%). Mirrors 0x4C5 byte 5 (D6, DC) when accepted (reply run). While an AC 0x4C5 is accepted, bytes 4-5 flip 0x9A7F -> 0x4870; while a DC 0x4C5 is accepted, bytes 6-7 flip 0x9A7F -> 0x4870 (16-bit fields, semantics not mapped).";
CM_ SG_ 820 DC_Charge_Limit "byte 0 (D1)";
BO_ 820 Charge_Limit_Status_334: 8 Vector__XXX
 SG_ DC_Charge_Limit : 0|8@1+ (0.5,0) [0|100] "%" Vector__XXX
CM_ BO_ 820 "a.k.a. BMS BMS_05_100ms_4 in gen5w_hu_rx.dbc";

CM_ "NOTE: 21 frame IDs in this file also appear in gen5w_hu_rx.dbc under the older opaque `<ECU>_<num>_<timing>_<num>` naming. Each carries an `a.k.a.` CM_ comment naming its gen5w equivalent; the gen5w duplicate definitions were folded into the semantic definitions rather than kept as second definitions of the same ID.";

CM_ "=== Frames below merged from gen5w_hu_rx.dbc ===";

BO_ 16 ACU_02_00ms: 8 ACU
 SG_ DATA : 0|64@1+ (1,0) [0|0] "" ACU

CM_ BO_ 16 "ACU ACU_02_00ms";
BO_ 54 VCU_01_10ms_1: 8 VCU
 SG_ DATA : 0|64@1+ (1,0) [0|0] "" VCU

CM_ BO_ 54 "VCU VCU_01_10ms_1";
BO_ 55 VCU_01_10ms_2: 8 VCU
 SG_ DATA : 0|64@1+ (1,0) [0|0] "" VCU

CM_ BO_ 55 "VCU VCU_01_10ms_2";
BO_ 75 YRS_01_10ms_1: 8 YRS
 SG_ DATA : 0|64@1+ (1,0) [0|0] "" YRS

CM_ BO_ 75 "YRS YRS_01_10ms_1";
BO_ 76 YRS_01_10ms_2: 8 YRS
 SG_ DATA : 0|64@1+ (1,0) [0|0] "" YRS

CM_ BO_ 76 "YRS YRS_01_10ms_2";
BO_ 77 YRS_01_10ms_3: 8 YRS
 SG_ DATA : 0|64@1+ (1,0) [0|0] "" YRS

CM_ BO_ 77 "YRS YRS_01_10ms_3";
BO_ 78 YRS_01_10ms_4: 8 YRS
 SG_ DATA : 0|64@1+ (1,0) [0|0] "" YRS

CM_ BO_ 78 "YRS YRS_01_10ms_4";
BO_ 86 BMS_26_500ms_1: 8 BMS
 SG_ DATA : 0|64@1+ (1,0) [0|0] "" BMS

CM_ BO_ 86 "BMS BMS_26_500ms_1";
BO_ 87 BMS_26_500ms_2: 8 BMS
 SG_ DATA : 0|64@1+ (1,0) [0|0] "" BMS

CM_ BO_ 87 "BMS BMS_26_500ms_2";
BO_ 88 BMS_26_500ms_3: 8 BMS
 SG_ DATA : 0|64@1+ (1,0) [0|0] "" BMS

CM_ BO_ 88 "BMS BMS_26_500ms_3";
BO_ 89 BMS_26_500ms_4: 8 BMS
 SG_ DATA : 0|64@1+ (1,0) [0|0] "" BMS

CM_ BO_ 89 "BMS BMS_26_500ms_4";
BO_ 97 ESC_01_10ms_1: 8 ESC
 SG_ DATA : 0|64@1+ (1,0) [0|0] "" ESC

CM_ BO_ 97 "ESC ESC_01_10ms_1";
BO_ 98 ESC_01_10ms_2: 8 ESC
 SG_ DATA : 0|64@1+ (1,0) [0|0] "" ESC

CM_ BO_ 98 "ESC ESC_01_10ms_2";
BO_ 99 ESC_01_10ms_3: 8 ESC
 SG_ DATA : 0|64@1+ (1,0) [0|0] "" ESC

CM_ BO_ 99 "ESC ESC_01_10ms_3";
BO_ 100 ESC_01_10ms_4: 8 ESC
 SG_ DATA : 0|64@1+ (1,0) [0|0] "" ESC

CM_ BO_ 100 "ESC ESC_01_10ms_4";
BO_ 102 IEB_01_10ms_1: 8 IEB
 SG_ DATA : 0|64@1+ (1,0) [0|0] "" IEB

CM_ BO_ 102 "IEB IEB_01_10ms_1";
BO_ 103 IEB_01_10ms_2: 8 IEB
 SG_ DATA : 0|64@1+ (1,0) [0|0] "" IEB

CM_ BO_ 103 "IEB IEB_01_10ms_2";
BO_ 104 IEB_01_10ms_3: 8 IEB
 SG_ DATA : 0|64@1+ (1,0) [0|0] "" IEB

CM_ BO_ 104 "IEB IEB_01_10ms_3";
BO_ 105 IEB_01_10ms_4: 8 IEB
 SG_ DATA : 0|64@1+ (1,0) [0|0] "" IEB

CM_ BO_ 105 "IEB IEB_01_10ms_4";
BO_ 111 ABS_ESC_01_10ms: 8 ABS
 SG_ DATA : 0|64@1+ (1,0) [0|0] "" ABS

CM_ BO_ 111 "ABS ABS_ESC_01_10ms";
BO_ 145 DATC_19_100ms_1: 8 DATC
 SG_ DATA : 0|64@1+ (1,0) [0|0] "" DATC

CM_ BO_ 145 "DATC DATC_19_100ms_1";
BO_ 146 DATC_19_100ms_2: 8 DATC
 SG_ DATA : 0|64@1+ (1,0) [0|0] "" DATC

CM_ BO_ 146 "DATC DATC_19_100ms_2";
BO_ 147 DATC_19_100ms_3: 8 DATC
 SG_ DATA : 0|64@1+ (1,0) [0|0] "" DATC

CM_ BO_ 147 "DATC DATC_19_100ms_3";
BO_ 148 DATC_19_100ms_4: 8 DATC
 SG_ DATA : 0|64@1+ (1,0) [0|0] "" DATC

CM_ BO_ 148 "DATC DATC_19_100ms_4";
BO_ 161 WHL_01_10ms_1: 8 WHL
 SG_ DATA : 0|64@1+ (1,0) [0|0] "" WHL

CM_ BO_ 161 "WHL WHL_01_10ms_1";
BO_ 163 WHL_01_10ms_3: 8 WHL
 SG_ DATA : 0|64@1+ (1,0) [0|0] "" WHL

CM_ BO_ 163 "WHL WHL_01_10ms_3";
BO_ 210 IAU_26_200ms: 8 IAU
 SG_ DATA : 0|64@1+ (1,0) [0|0] "" IAU

CM_ BO_ 210 "IAU IAU_26_200ms";
BO_ 230 ESC_02_10ms_1: 8 ESC
 SG_ DATA : 0|64@1+ (1,0) [0|0] "" ESC

CM_ BO_ 230 "ESC ESC_02_10ms_1";
BO_ 231 ESC_02_10ms_2: 8 ESC
 SG_ DATA : 0|64@1+ (1,0) [0|0] "" ESC

CM_ BO_ 231 "ESC ESC_02_10ms_2";
BO_ 232 ESC_02_10ms_3: 8 ESC
 SG_ DATA : 0|64@1+ (1,0) [0|0] "" ESC

CM_ BO_ 232 "ESC ESC_02_10ms_3";
BO_ 233 ESC_02_10ms_4: 8 ESC
 SG_ DATA : 0|64@1+ (1,0) [0|0] "" ESC

CM_ BO_ 233 "ESC ESC_02_10ms_4";
BO_ 235 MDPS_01_10ms_1: 8 MDPS
 SG_ DATA : 0|64@1+ (1,0) [0|0] "" MDPS

CM_ BO_ 235 "MDPS MDPS_01_10ms_1";
BO_ 236 MDPS_01_10ms_2: 8 MDPS
 SG_ DATA : 0|64@1+ (1,0) [0|0] "" MDPS

CM_ BO_ 236 "MDPS MDPS_01_10ms_2";
BO_ 237 MDPS_01_10ms_3: 8 MDPS
 SG_ DATA : 0|64@1+ (1,0) [0|0] "" MDPS

CM_ BO_ 237 "MDPS MDPS_01_10ms_3";
BO_ 246 VCU_02_10ms_1: 8 VCU
 SG_ DATA : 0|64@1+ (1,0) [0|0] "" VCU

CM_ BO_ 246 "VCU VCU_02_10ms_1";
BO_ 247 VCU_02_10ms_2: 8 VCU
 SG_ DATA : 0|64@1+ (1,0) [0|0] "" VCU

CM_ BO_ 247 "VCU VCU_02_10ms_2";
BO_ 248 VCU_02_10ms_3: 8 VCU
 SG_ DATA : 0|64@1+ (1,0) [0|0] "" VCU

CM_ BO_ 248 "VCU VCU_02_10ms_3";
BO_ 249 VCU_02_10ms_4: 8 VCU
 SG_ DATA : 0|64@1+ (1,0) [0|0] "" VCU

CM_ BO_ 249 "VCU VCU_02_10ms_4";
BO_ 267 MCU_01_10ms_1: 8 MCU
 SG_ DATA : 0|64@1+ (1,0) [0|0] "" MCU

CM_ BO_ 267 "MCU MCU_01_10ms_1";
BO_ 268 MCU_01_10ms_2: 8 MCU
 SG_ DATA : 0|64@1+ (1,0) [0|0] "" MCU

CM_ BO_ 268 "MCU MCU_01_10ms_2";
BO_ 269 MCU_01_10ms_3: 8 MCU
 SG_ DATA : 0|64@1+ (1,0) [0|0] "" MCU

CM_ BO_ 269 "MCU MCU_01_10ms_3";
BO_ 270 MCU_01_10ms_4: 8 MCU
 SG_ DATA : 0|64@1+ (1,0) [0|0] "" MCU

CM_ BO_ 270 "MCU MCU_01_10ms_4";
BO_ 283 FR_CMR_01_10ms_1: 8 FR
 SG_ DATA : 0|64@1+ (1,0) [0|0] "" FR

CM_ BO_ 283 "FR FR_CMR_01_10ms_1";
BO_ 284 FR_CMR_01_10ms_2: 8 FR
 SG_ DATA : 0|64@1+ (1,0) [0|0] "" FR

CM_ BO_ 284 "FR FR_CMR_01_10ms_2";
BO_ 289 MCU_02_10ms_1: 8 MCU
 SG_ DATA : 0|64@1+ (1,0) [0|0] "" MCU

CM_ BO_ 289 "MCU MCU_02_10ms_1";
BO_ 290 MCU_02_10ms_2: 8 MCU
 SG_ DATA : 0|64@1+ (1,0) [0|0] "" MCU

CM_ BO_ 290 "MCU MCU_02_10ms_2";
BO_ 291 MCU_02_10ms_3: 8 MCU
 SG_ DATA : 0|64@1+ (1,0) [0|0] "" MCU

CM_ BO_ 291 "MCU MCU_02_10ms_3";
BO_ 292 MCU_02_10ms_4: 8 MCU
 SG_ DATA : 0|64@1+ (1,0) [0|0] "" MCU

CM_ BO_ 292 "MCU MCU_02_10ms_4";
BO_ 294 SAS_01_10ms_1: 8 SAS
 SG_ DATA : 0|64@1+ (1,0) [0|0] "" SAS

CM_ BO_ 294 "SAS SAS_01_10ms_1";
BO_ 295 SAS_01_10ms_2: 8 SAS
 SG_ DATA : 0|64@1+ (1,0) [0|0] "" SAS

CM_ BO_ 295 "SAS SAS_01_10ms_2";
BO_ 299 ADAS_CMD_30_10ms_1: 8 ADAS
 SG_ DATA : 0|64@1+ (1,0) [0|0] "" ADAS

CM_ BO_ 299 "ADAS ADAS_CMD_30_10ms_1";
BO_ 300 ADAS_CMD_30_10ms_2: 8 ADAS
 SG_ DATA : 0|64@1+ (1,0) [0|0] "" ADAS

CM_ BO_ 300 "ADAS ADAS_CMD_30_10ms_2";
BO_ 310 BAT_01_10ms_1: 8 BAT
 SG_ DATA : 0|64@1+ (1,0) [0|0] "" BAT

CM_ BO_ 310 "BAT BAT_01_10ms_1";
BO_ 311 BAT_01_10ms_2: 8 BAT
 SG_ DATA : 0|64@1+ (1,0) [0|0] "" BAT

CM_ BO_ 311 "BAT BAT_01_10ms_2";
BO_ 315 FR_CMR_05_00ms_1: 8 FR
 SG_ DATA : 0|64@1+ (1,0) [0|0] "" FR

CM_ BO_ 315 "FR FR_CMR_05_00ms_1";
BO_ 316 FR_CMR_05_00ms_2: 8 FR
 SG_ DATA : 0|64@1+ (1,0) [0|0] "" FR

CM_ BO_ 316 "FR FR_CMR_05_00ms_2";
BO_ 317 FR_CMR_05_00ms_3: 8 FR
 SG_ DATA : 0|64@1+ (1,0) [0|0] "" FR

CM_ BO_ 317 "FR FR_CMR_05_00ms_3";
BO_ 318 FR_CMR_05_00ms_4: 8 FR
 SG_ DATA : 0|64@1+ (1,0) [0|0] "" FR

CM_ BO_ 318 "FR FR_CMR_05_00ms_4";
BO_ 320 FR_RDR_01_10ms: 8 FR
 SG_ DATA : 0|64@1+ (1,0) [0|0] "" FR

CM_ BO_ 320 "FR FR_RDR_01_10ms";
BO_ 326 DATC_01_20ms_1: 8 DATC
 SG_ DATA : 0|64@1+ (1,0) [0|0] "" DATC

CM_ BO_ 326 "DATC DATC_01_20ms_1";
BO_ 327 DATC_01_20ms_2: 8 DATC
 SG_ DATA : 0|64@1+ (1,0) [0|0] "" DATC

CM_ BO_ 327 "DATC DATC_01_20ms_2";
BO_ 328 DATC_01_20ms_3: 8 DATC
 SG_ DATA : 0|64@1+ (1,0) [0|0] "" DATC

CM_ BO_ 328 "DATC DATC_01_20ms_3";
BO_ 329 DATC_01_20ms_4: 8 DATC
 SG_ DATA : 0|64@1+ (1,0) [0|0] "" DATC

CM_ BO_ 329 "DATC DATC_01_20ms_4";
BO_ 337 BMS_10_100ms_1: 8 BMS
 SG_ DATA : 0|64@1+ (1,0) [0|0] "" BMS

CM_ BO_ 337 "BMS BMS_10_100ms_1";
BO_ 339 BMS_10_100ms_3: 8 BMS
 SG_ DATA : 0|64@1+ (1,0) [0|0] "" BMS

CM_ BO_ 339 "BMS BMS_10_100ms_3";
BO_ 340 BMS_10_100ms_4: 8 BMS
 SG_ DATA : 0|64@1+ (1,0) [0|0] "" BMS

CM_ BO_ 340 "BMS BMS_10_100ms_4";
BO_ 342 APSB_01_10ms_1: 8 APSB
 SG_ DATA : 0|64@1+ (1,0) [0|0] "" APSB

CM_ BO_ 342 "APSB APSB_01_10ms_1";
BO_ 343 APSB_01_10ms_2: 8 APSB
 SG_ DATA : 0|64@1+ (1,0) [0|0] "" APSB

CM_ BO_ 343 "APSB APSB_01_10ms_2";
BO_ 353 ADAS_CMD_10_20ms_1: 8 ADAS
 SG_ DATA : 0|64@1+ (1,0) [0|0] "" ADAS

CM_ BO_ 353 "ADAS ADAS_CMD_10_20ms_1";
BO_ 354 ADAS_CMD_10_20ms_2: 8 ADAS
 SG_ DATA : 0|64@1+ (1,0) [0|0] "" ADAS

CM_ BO_ 354 "ADAS ADAS_CMD_10_20ms_2";
BO_ 358 ADAS_PRK_20_20ms_1: 8 ADAS
 SG_ DATA : 0|64@1+ (1,0) [0|0] "" ADAS

CM_ BO_ 358 "ADAS ADAS_PRK_20_20ms_1";
BO_ 359 ADAS_PRK_20_20ms_2: 8 ADAS
 SG_ DATA : 0|64@1+ (1,0) [0|0] "" ADAS

CM_ BO_ 359 "ADAS ADAS_PRK_20_20ms_2";
BO_ 360 ADAS_PRK_20_20ms_3: 8 ADAS
 SG_ DATA : 0|64@1+ (1,0) [0|0] "" ADAS

CM_ BO_ 360 "ADAS ADAS_PRK_20_20ms_3";
BO_ 363 ADAS_PRK_21_20ms_1: 8 ADAS
 SG_ DATA : 0|64@1+ (1,0) [0|0] "" ADAS

CM_ BO_ 363 "ADAS ADAS_PRK_21_20ms_1";
BO_ 364 ADAS_PRK_21_20ms_2: 8 ADAS
 SG_ DATA : 0|64@1+ (1,0) [0|0] "" ADAS

CM_ BO_ 364 "ADAS ADAS_PRK_21_20ms_2";
BO_ 365 ADAS_PRK_21_20ms_3: 8 ADAS
 SG_ DATA : 0|64@1+ (1,0) [0|0] "" ADAS

CM_ BO_ 365 "ADAS ADAS_PRK_21_20ms_3";
BO_ 366 ADAS_PRK_21_20ms_4: 8 ADAS
 SG_ DATA : 0|64@1+ (1,0) [0|0] "" ADAS

CM_ BO_ 366 "ADAS ADAS_PRK_21_20ms_4";
BO_ 369 ADAS_PRK_10_20ms_1: 8 ADAS
 SG_ DATA : 0|64@1+ (1,0) [0|0] "" ADAS

CM_ BO_ 369 "ADAS ADAS_PRK_10_20ms_1";
BO_ 370 ADAS_PRK_10_20ms_2: 8 ADAS
 SG_ DATA : 0|64@1+ (1,0) [0|0] "" ADAS

CM_ BO_ 370 "ADAS ADAS_PRK_10_20ms_2";
BO_ 374 ESC_03_20ms_1: 8 ESC
 SG_ DATA : 0|64@1+ (1,0) [0|0] "" ESC

CM_ BO_ 374 "ESC ESC_03_20ms_1";
BO_ 375 ESC_03_20ms_2: 8 ESC
 SG_ DATA : 0|64@1+ (1,0) [0|0] "" ESC

CM_ BO_ 375 "ESC ESC_03_20ms_2";
BO_ 376 ESC_03_20ms_3: 8 ESC
 SG_ DATA : 0|64@1+ (1,0) [0|0] "" ESC

CM_ BO_ 376 "ESC ESC_03_20ms_3";
BO_ 384 CLU_17_20ms: 8 CLU
 SG_ DATA : 0|64@1+ (1,0) [0|0] "" CLU

CM_ BO_ 384 "CLU CLU_17_20ms";
BO_ 389 CLU_18_20ms: 8 CLU
 SG_ DATA : 0|64@1+ (1,0) [0|0] "" CLU

CM_ BO_ 389 "CLU CLU_18_20ms";
BO_ 395 ADAS_PRK_22_20ms_1: 8 ADAS
 SG_ DATA : 0|64@1+ (1,0) [0|0] "" ADAS

CM_ BO_ 395 "ADAS ADAS_PRK_22_20ms_1";
BO_ 396 ADAS_PRK_22_20ms_2: 8 ADAS
 SG_ DATA : 0|64@1+ (1,0) [0|0] "" ADAS

CM_ BO_ 396 "ADAS ADAS_PRK_22_20ms_2";
BO_ 397 ADAS_PRK_22_20ms_3: 8 ADAS
 SG_ DATA : 0|64@1+ (1,0) [0|0] "" ADAS

CM_ BO_ 397 "ADAS ADAS_PRK_22_20ms_3";
BO_ 398 ADAS_PRK_22_20ms_4: 8 ADAS
 SG_ DATA : 0|64@1+ (1,0) [0|0] "" ADAS

CM_ BO_ 398 "ADAS ADAS_PRK_22_20ms_4";
BO_ 406 ADAS_CMD_33_10ms_1: 8 ADAS
 SG_ DATA : 0|64@1+ (1,0) [0|0] "" ADAS

CM_ BO_ 406 "ADAS ADAS_CMD_33_10ms_1";
BO_ 407 ADAS_CMD_33_10ms_2: 8 ADAS
 SG_ DATA : 0|64@1+ (1,0) [0|0] "" ADAS

CM_ BO_ 407 "ADAS ADAS_CMD_33_10ms_2";
BO_ 408 ADAS_CMD_33_10ms_3: 8 ADAS
 SG_ DATA : 0|64@1+ (1,0) [0|0] "" ADAS

CM_ BO_ 408 "ADAS ADAS_CMD_33_10ms_3";
BO_ 409 ADAS_CMD_33_10ms_4: 8 ADAS
 SG_ DATA : 0|64@1+ (1,0) [0|0] "" ADAS

CM_ BO_ 409 "ADAS ADAS_CMD_33_10ms_4";
BO_ 411 VCMS_01_10ms_1: 8 VCMS
 SG_ DATA : 0|64@1+ (1,0) [0|0] "" VCMS

CM_ BO_ 411 "VCMS VCMS_01_10ms_1";
BO_ 412 VCMS_01_10ms_2: 8 VCMS
 SG_ DATA : 0|64@1+ (1,0) [0|0] "" VCMS

CM_ BO_ 412 "VCMS VCMS_01_10ms_2";
BO_ 413 VCMS_01_10ms_3: 8 VCMS
 SG_ DATA : 0|64@1+ (1,0) [0|0] "" VCMS

CM_ BO_ 413 "VCMS VCMS_01_10ms_3";
BO_ 414 VCMS_01_10ms_4: 8 VCMS
 SG_ DATA : 0|64@1+ (1,0) [0|0] "" VCMS

CM_ BO_ 414 "VCMS VCMS_01_10ms_4";
BO_ 417 ADAS_CMD_20_20ms_1: 8 ADAS
 SG_ DATA : 0|64@1+ (1,0) [0|0] "" ADAS

CM_ BO_ 417 "ADAS ADAS_CMD_20_20ms_1";
BO_ 418 ADAS_CMD_20_20ms_2: 8 ADAS
 SG_ DATA : 0|64@1+ (1,0) [0|0] "" ADAS

CM_ BO_ 418 "ADAS ADAS_CMD_20_20ms_2";
BO_ 419 ADAS_CMD_20_20ms_3: 8 ADAS
 SG_ DATA : 0|64@1+ (1,0) [0|0] "" ADAS

CM_ BO_ 419 "ADAS ADAS_CMD_20_20ms_3";
BO_ 420 ADAS_CMD_20_20ms_4: 8 ADAS
 SG_ DATA : 0|64@1+ (1,0) [0|0] "" ADAS

CM_ BO_ 420 "ADAS ADAS_CMD_20_20ms_4";
BO_ 427 CLU_01_20ms_1: 8 CLU
 SG_ DATA : 0|64@1+ (1,0) [0|0] "" CLU

CM_ BO_ 427 "CLU CLU_01_20ms_1";
BO_ 433 DATC_02_20ms_1: 8 DATC
 SG_ DATA : 0|64@1+ (1,0) [0|0] "" DATC

CM_ BO_ 433 "DATC DATC_02_20ms_1";
BO_ 434 DATC_02_20ms_2: 8 DATC
 SG_ DATA : 0|64@1+ (1,0) [0|0] "" DATC

CM_ BO_ 434 "DATC DATC_02_20ms_2";
BO_ 435 DATC_02_20ms_3: 8 DATC
 SG_ DATA : 0|64@1+ (1,0) [0|0] "" DATC

CM_ BO_ 435 "DATC DATC_02_20ms_3";
BO_ 436 DATC_02_20ms_4: 8 DATC
 SG_ DATA : 0|64@1+ (1,0) [0|0] "" DATC

CM_ BO_ 436 "DATC DATC_02_20ms_4";
BO_ 438 FR_CMR_03_50ms_1: 8 FR
 SG_ DATA : 0|64@1+ (1,0) [0|0] "" FR

CM_ BO_ 438 "FR FR_CMR_03_50ms_1";
BO_ 439 FR_CMR_03_50ms_2: 8 FR
 SG_ DATA : 0|64@1+ (1,0) [0|0] "" FR

CM_ BO_ 439 "FR FR_CMR_03_50ms_2";
BO_ 440 FR_CMR_03_50ms_3: 8 FR
 SG_ DATA : 0|64@1+ (1,0) [0|0] "" FR

CM_ BO_ 440 "FR FR_CMR_03_50ms_3";
BO_ 441 FR_CMR_03_50ms_4: 8 FR
 SG_ DATA : 0|64@1+ (1,0) [0|0] "" FR

CM_ BO_ 441 "FR FR_CMR_03_50ms_4";
BO_ 443 RR_C_RDR_02_50ms_1: 8 RR
 SG_ DATA : 0|64@1+ (1,0) [0|0] "" RR

CM_ BO_ 443 "RR RR_C_RDR_02_50ms_1";
BO_ 444 RR_C_RDR_02_50ms_2: 8 RR
 SG_ DATA : 0|64@1+ (1,0) [0|0] "" RR

CM_ BO_ 444 "RR RR_C_RDR_02_50ms_2";
BO_ 445 RR_C_RDR_02_50ms_3: 8 RR
 SG_ DATA : 0|64@1+ (1,0) [0|0] "" RR

CM_ BO_ 445 "RR RR_C_RDR_02_50ms_3";
BO_ 481 ADAS_CMD_31_50ms_1: 8 ADAS
 SG_ DATA : 0|64@1+ (1,0) [0|0] "" ADAS

CM_ BO_ 481 "ADAS ADAS_CMD_31_50ms_1";
BO_ 482 ADAS_CMD_31_50ms_2: 8 ADAS
 SG_ DATA : 0|64@1+ (1,0) [0|0] "" ADAS

CM_ BO_ 482 "ADAS ADAS_CMD_31_50ms_2";
BO_ 486 RR_C_RDR_01_50ms_1: 8 RR
 SG_ DATA : 0|64@1+ (1,0) [0|0] "" RR

CM_ BO_ 486 "RR RR_C_RDR_01_50ms_1";
BO_ 487 RR_C_RDR_01_50ms_2: 8 RR
 SG_ DATA : 0|64@1+ (1,0) [0|0] "" RR

CM_ BO_ 487 "RR RR_C_RDR_01_50ms_2";
BO_ 491 ADAS_CMD_32_50ms_1: 8 ADAS
 SG_ DATA : 0|64@1+ (1,0) [0|0] "" ADAS

CM_ BO_ 491 "ADAS ADAS_CMD_32_50ms_1";
BO_ 492 ADAS_CMD_32_50ms_2: 8 ADAS
 SG_ DATA : 0|64@1+ (1,0) [0|0] "" ADAS

CM_ BO_ 492 "ADAS ADAS_CMD_32_50ms_2";
BO_ 493 ADAS_CMD_32_50ms_3: 8 ADAS
 SG_ DATA : 0|64@1+ (1,0) [0|0] "" ADAS

CM_ BO_ 493 "ADAS ADAS_CMD_32_50ms_3";
BO_ 494 ADAS_CMD_32_50ms_4: 8 ADAS
 SG_ DATA : 0|64@1+ (1,0) [0|0] "" ADAS

CM_ BO_ 494 "ADAS ADAS_CMD_32_50ms_4";
BO_ 497 EPB_01_50ms_1: 8 EPB
 SG_ DATA : 0|64@1+ (1,0) [0|0] "" EPB

CM_ BO_ 497 "EPB EPB_01_50ms_1";
BO_ 502 BMS_08_100ms_1: 8 BMS
 SG_ DATA : 0|64@1+ (1,0) [0|0] "" BMS

CM_ BO_ 502 "BMS BMS_08_100ms_1";
BO_ 503 BMS_08_100ms_2: 8 BMS
 SG_ DATA : 0|64@1+ (1,0) [0|0] "" BMS

CM_ BO_ 503 "BMS BMS_08_100ms_2";
BO_ 504 BMS_08_100ms_3: 8 BMS
 SG_ DATA : 0|64@1+ (1,0) [0|0] "" BMS

CM_ BO_ 504 "BMS BMS_08_100ms_3";
BO_ 507 FR_CMR_02_100ms_1: 8 FR
 SG_ DATA : 0|64@1+ (1,0) [0|0] "" FR

CM_ BO_ 507 "FR FR_CMR_02_100ms_1";
BO_ 508 FR_CMR_02_100ms_2: 8 FR
 SG_ DATA : 0|64@1+ (1,0) [0|0] "" FR

CM_ BO_ 508 "FR FR_CMR_02_100ms_2";
BO_ 509 FR_CMR_02_100ms_3: 8 FR
 SG_ DATA : 0|64@1+ (1,0) [0|0] "" FR

CM_ BO_ 509 "FR FR_CMR_02_100ms_3";
BO_ 510 FR_CMR_02_100ms_4: 8 FR
 SG_ DATA : 0|64@1+ (1,0) [0|0] "" FR

CM_ BO_ 510 "FR FR_CMR_02_100ms_4";
BO_ 512 ADAS_CMD_21_50ms: 8 ADAS
 SG_ DATA : 0|64@1+ (1,0) [0|0] "" ADAS

CM_ BO_ 512 "ADAS ADAS_CMD_21_50ms";
BO_ 518 ICSC_02_100ms_1: 8 ICSC
 SG_ DATA : 0|64@1+ (1,0) [0|0] "" ICSC

CM_ BO_ 518 "ICSC ICSC_02_100ms_1";
BO_ 519 ICSC_02_100ms_2: 8 ICSC
 SG_ DATA : 0|64@1+ (1,0) [0|0] "" ICSC

CM_ BO_ 519 "ICSC ICSC_02_100ms_2";
BO_ 520 ICSC_02_100ms_3: 8 ICSC
 SG_ DATA : 0|64@1+ (1,0) [0|0] "" ICSC

CM_ BO_ 520 "ICSC ICSC_02_100ms_3";
BO_ 523 ACU_01_100ms_1: 8 ACU
 SG_ DATA : 0|64@1+ (1,0) [0|0] "" ACU

CM_ BO_ 523 "ACU ACU_01_100ms_1";
BO_ 524 ACU_01_100ms_2: 8 ACU
 SG_ DATA : 0|64@1+ (1,0) [0|0] "" ACU

CM_ BO_ 524 "ACU ACU_01_100ms_2";
BO_ 566 BMS_01_100ms_1: 8 BMS
 SG_ DATA : 0|64@1+ (1,0) [0|0] "" BMS

CM_ BO_ 566 "BMS BMS_01_100ms_1";
BO_ 567 BMS_01_100ms_2: 8 BMS
 SG_ DATA : 0|64@1+ (1,0) [0|0] "" BMS

CM_ BO_ 567 "BMS BMS_01_100ms_2";
BO_ 568 BMS_01_100ms_3: 8 BMS
 SG_ DATA : 0|64@1+ (1,0) [0|0] "" BMS

CM_ BO_ 568 "BMS BMS_01_100ms_3";
BO_ 569 BMS_01_100ms_4: 8 BMS
 SG_ DATA : 0|64@1+ (1,0) [0|0] "" BMS

CM_ BO_ 569 "BMS BMS_01_100ms_4";
BO_ 582 BMS_23_500ms_1: 8 BMS
 SG_ DATA : 0|64@1+ (1,0) [0|0] "" BMS

CM_ BO_ 582 "BMS BMS_23_500ms_1";
BO_ 583 BMS_23_500ms_2: 8 BMS
 SG_ DATA : 0|64@1+ (1,0) [0|0] "" BMS

CM_ BO_ 583 "BMS BMS_23_500ms_2";
BO_ 584 BMS_23_500ms_3: 8 BMS
 SG_ DATA : 0|64@1+ (1,0) [0|0] "" BMS

CM_ BO_ 584 "BMS BMS_23_500ms_3";
BO_ 585 BMS_23_500ms_4: 8 BMS
 SG_ DATA : 0|64@1+ (1,0) [0|0] "" BMS

CM_ BO_ 585 "BMS BMS_23_500ms_4";
BO_ 593 MCU_03_100ms_1: 8 MCU
 SG_ DATA : 0|64@1+ (1,0) [0|0] "" MCU

CM_ BO_ 593 "MCU MCU_03_100ms_1";
BO_ 594 MCU_03_100ms_2: 8 MCU
 SG_ DATA : 0|64@1+ (1,0) [0|0] "" MCU

CM_ BO_ 594 "MCU MCU_03_100ms_2";
BO_ 595 MCU_03_100ms_3: 8 MCU
 SG_ DATA : 0|64@1+ (1,0) [0|0] "" MCU

CM_ BO_ 595 "MCU MCU_03_100ms_3";
BO_ 598 LDC_01_100ms_1: 8 LDC
 SG_ DATA : 0|64@1+ (1,0) [0|0] "" LDC

CM_ BO_ 598 "LDC LDC_01_100ms_1";
BO_ 599 LDC_01_100ms_2: 8 LDC
 SG_ DATA : 0|64@1+ (1,0) [0|0] "" LDC

CM_ BO_ 599 "LDC LDC_01_100ms_2";
BO_ 600 LDC_01_100ms_3: 8 LDC
 SG_ DATA : 0|64@1+ (1,0) [0|0] "" LDC

CM_ BO_ 600 "LDC LDC_01_100ms_3";
BO_ 601 LDC_01_100ms_4: 8 LDC
 SG_ DATA : 0|64@1+ (1,0) [0|0] "" LDC

CM_ BO_ 601 "LDC LDC_01_100ms_4";
BO_ 603 BMS_04_100ms_1: 8 BMS
 SG_ DATA : 0|64@1+ (1,0) [0|0] "" BMS

CM_ BO_ 603 "BMS BMS_04_100ms_1";
BO_ 604 BMS_04_100ms_2: 8 BMS
 SG_ DATA : 0|64@1+ (1,0) [0|0] "" BMS

CM_ BO_ 604 "BMS BMS_04_100ms_2";
BO_ 606 BMS_04_100ms_4: 8 BMS
 SG_ DATA : 0|64@1+ (1,0) [0|0] "" BMS

CM_ BO_ 606 "BMS BMS_04_100ms_4";
BO_ 630 BMS_24_500ms_1: 8 BMS
 SG_ DATA : 0|64@1+ (1,0) [0|0] "" BMS

CM_ BO_ 630 "BMS BMS_24_500ms_1";
BO_ 631 BMS_24_500ms_2: 8 BMS
 SG_ DATA : 0|64@1+ (1,0) [0|0] "" BMS

CM_ BO_ 631 "BMS BMS_24_500ms_2";
BO_ 632 BMS_24_500ms_3: 8 BMS
 SG_ DATA : 0|64@1+ (1,0) [0|0] "" BMS

CM_ BO_ 632 "BMS BMS_24_500ms_3";
BO_ 633 BMS_24_500ms_4: 8 BMS
 SG_ DATA : 0|64@1+ (1,0) [0|0] "" BMS

CM_ BO_ 633 "BMS BMS_24_500ms_4";
BO_ 683 VCU_04_100ms_1: 8 VCU
 SG_ DATA : 0|64@1+ (1,0) [0|0] "" VCU

CM_ BO_ 683 "VCU VCU_04_100ms_1";
BO_ 684 VCU_04_100ms_2: 8 VCU
 SG_ Climate_Setpoint_Raw : 32|8@1+ (0.5,14) [14|32] "C" VCU

CM_ BO_ 684 "VCU VCU_04_100ms_2 (0x2AC). Byte 4 (D5) carries the cabin climate setpoint in the same (0.5,14) encoding as 0x380 and 0x39B: 00 FF FF 40 06 40 84 50 = 17.0 C, 00 FF FF 40 10 40 84 50 = 22.0 C, 00 FF FF 40 16 40 84 50 = 25.0 C; the HVAC-off payload is 00 FF FF 00 00 40 00 50 (raw 0), so the field is only meaningful while the HVAC runs. Timing (2026-11-03 defrost captures): 0x39B byte 1 (D2) changes first, 0x2AC byte 4 (D5) follows ~0.5 s, 0x380 reports it another ~1.2 s later. Remaining bytes not decoded (appear to be status/counter).";
CM_ SG_ 684 Climate_Setpoint_Raw "byte 4 (D5): 0x06=17.0 C, 0x10=22.0 C, 0x11=22.5 C, 0x12=23.0 C, 0x16=25.0 C; 0x00 = HVAC off";
BO_ 686 VCU_04_100ms_4: 8 VCU
 SG_ DATA : 0|64@1+ (1,0) [0|0] "" VCU

CM_ BO_ 686 "VCU VCU_04_100ms_4";
BO_ 694 VCU_05_100ms_1: 8 VCU
 SG_ DATA : 0|64@1+ (1,0) [0|0] "" VCU

CM_ BO_ 694 "VCU VCU_05_100ms_1";
BO_ 695 VCU_05_100ms_2: 8 VCU
 SG_ DATA : 0|64@1+ (1,0) [0|0] "" VCU

CM_ BO_ 695 "VCU VCU_05_100ms_2";
BO_ 696 VCU_05_100ms_3: 8 VCU
 SG_ DATA : 0|64@1+ (1,0) [0|0] "" VCU

CM_ BO_ 696 "VCU VCU_05_100ms_3";
BO_ 697 VCU_05_100ms_4: 8 VCU
 SG_ DATA : 0|64@1+ (1,0) [0|0] "" VCU

CM_ BO_ 697 "VCU VCU_05_100ms_4";
BO_ 699 FR_CMR_04_40ms_1: 8 FR
 SG_ DATA : 0|64@1+ (1,0) [0|0] "" FR

CM_ BO_ 699 "FR FR_CMR_04_40ms_1";
BO_ 700 FR_CMR_04_40ms_2: 8 FR
 SG_ DATA : 0|64@1+ (1,0) [0|0] "" FR

CM_ BO_ 700 "FR FR_CMR_04_40ms_2";
BO_ 701 FR_CMR_04_40ms_3: 8 FR
 SG_ DATA : 0|64@1+ (1,0) [0|0] "" FR

CM_ BO_ 701 "FR FR_CMR_04_40ms_3";
BO_ 702 FR_CMR_04_40ms_4: 8 FR
 SG_ DATA : 0|64@1+ (1,0) [0|0] "" FR

CM_ BO_ 702 "FR FR_CMR_04_40ms_4";
BO_ 726 MCU_06_200ms_1: 8 MCU
 SG_ DATA : 0|64@1+ (1,0) [0|0] "" MCU

CM_ BO_ 726 "MCU MCU_06_200ms_1";
BO_ 727 MCU_06_200ms_2: 8 MCU
 SG_ DATA : 0|64@1+ (1,0) [0|0] "" MCU

CM_ BO_ 727 "MCU MCU_06_200ms_2";
BO_ 728 MCU_06_200ms_3: 8 MCU
 SG_ DATA : 0|64@1+ (1,0) [0|0] "" MCU

CM_ BO_ 728 "MCU MCU_06_200ms_3";
BO_ 729 MCU_06_200ms_4: 8 MCU
 SG_ DATA : 0|64@1+ (1,0) [0|0] "" MCU

CM_ BO_ 729 "MCU MCU_06_200ms_4";
BO_ 737 VCU_03_100ms_1: 8 VCU
 SG_ DATA : 0|64@1+ (1,0) [0|0] "" VCU

CM_ BO_ 737 "VCU VCU_03_100ms_1";
BO_ 738 VCU_03_100ms_2: 8 VCU
 SG_ DATA : 0|64@1+ (1,0) [0|0] "" VCU

CM_ BO_ 738 "VCU VCU_03_100ms_2";
BO_ 739 VCU_03_100ms_3: 8 VCU
 SG_ DATA : 0|64@1+ (1,0) [0|0] "" VCU

CM_ BO_ 739 "VCU VCU_03_100ms_3";
BO_ 740 VCU_03_100ms_4: 8 VCU
 SG_ DATA : 0|64@1+ (1,0) [0|0] "" VCU

CM_ BO_ 740 "VCU VCU_03_100ms_4";
BO_ 742 OBC_01_100ms_1: 8 OBC
 SG_ DATA : 0|64@1+ (1,0) [0|0] "" OBC

CM_ BO_ 742 "OBC OBC_01_100ms_1";
BO_ 743 OBC_01_100ms_2: 8 OBC
 SG_ DATA : 0|64@1+ (1,0) [0|0] "" OBC

CM_ BO_ 743 "OBC OBC_01_100ms_2";
BO_ 744 OBC_01_100ms_3: 8 OBC
 SG_ DATA : 0|64@1+ (1,0) [0|0] "" OBC

CM_ BO_ 744 "OBC OBC_01_100ms_3";
BO_ 745 OBC_01_100ms_4: 8 OBC
 SG_ DATA : 0|64@1+ (1,0) [0|0] "" OBC

CM_ BO_ 745 "OBC OBC_01_100ms_4";
BO_ 763 BMS_02_100ms_1: 8 BMS
 SG_ DATA : 0|64@1+ (1,0) [0|0] "" BMS

CM_ BO_ 763 "BMS BMS_02_100ms_1";
BO_ 765 BMS_02_100ms_3: 8 BMS
 SG_ DATA : 0|64@1+ (1,0) [0|0] "" BMS

CM_ BO_ 765 "BMS BMS_02_100ms_3";
BO_ 766 BMS_02_100ms_4: 8 BMS
 SG_ DATA : 0|64@1+ (1,0) [0|0] "" BMS

CM_ BO_ 766 "BMS BMS_02_100ms_4";
BO_ 774 MCU_09_1000ms_1: 8 MCU
 SG_ DATA : 0|64@1+ (1,0) [0|0] "" MCU

CM_ BO_ 774 "MCU MCU_09_1000ms_1";
BO_ 775 MCU_09_1000ms_2: 8 MCU
 SG_ DATA : 0|64@1+ (1,0) [0|0] "" MCU

CM_ BO_ 775 "MCU MCU_09_1000ms_2";
BO_ 776 MCU_09_1000ms_3: 8 MCU
 SG_ DATA : 0|64@1+ (1,0) [0|0] "" MCU

CM_ BO_ 776 "MCU MCU_09_1000ms_3";
BO_ 777 MCU_09_1000ms_4: 8 MCU
 SG_ DATA : 0|64@1+ (1,0) [0|0] "" MCU

CM_ BO_ 777 "MCU MCU_09_1000ms_4";
BO_ 779 VCMS_02_100ms_1: 8 VCMS
 SG_ DATA : 0|64@1+ (1,0) [0|0] "" VCMS

CM_ BO_ 779 "VCMS VCMS_02_100ms_1";
BO_ 780 VCMS_02_100ms_2: 8 VCMS
 SG_ DATA : 0|64@1+ (1,0) [0|0] "" VCMS

CM_ BO_ 780 "VCMS VCMS_02_100ms_2";
BO_ 781 VCMS_02_100ms_3: 8 VCMS
 SG_ DATA : 0|64@1+ (1,0) [0|0] "" VCMS

CM_ BO_ 781 "VCMS VCMS_02_100ms_3";
BO_ 796 DATC_31_1000ms_2: 8 DATC
 SG_ DATA : 0|64@1+ (1,0) [0|0] "" DATC

CM_ BO_ 796 "DATC DATC_31_1000ms_2";
BO_ 797 DATC_31_1000ms_3: 8 DATC
 SG_ DATA : 0|64@1+ (1,0) [0|0] "" DATC

CM_ BO_ 797 "DATC DATC_31_1000ms_3";
BO_ 798 DATC_31_1000ms_4: 8 DATC
 SG_ DATA : 0|64@1+ (1,0) [0|0] "" DATC

CM_ BO_ 798 "DATC DATC_31_1000ms_4";
BO_ 801 VCMS_03_100ms_1: 8 VCMS
 SG_ DATA : 0|64@1+ (1,0) [0|0] "" VCMS

CM_ BO_ 801 "VCMS VCMS_03_100ms_1";
BO_ 802 VCMS_03_100ms_2: 8 VCMS
 SG_ DATA : 0|64@1+ (1,0) [0|0] "" VCMS

CM_ BO_ 802 "VCMS VCMS_03_100ms_2";
BO_ 803 VCMS_03_100ms_3: 8 VCMS
 SG_ DATA : 0|64@1+ (1,0) [0|0] "" VCMS

CM_ BO_ 803 "VCMS VCMS_03_100ms_3";
BO_ 804 VCMS_03_100ms_4: 8 VCMS
 SG_ DATA : 0|64@1+ (1,0) [0|0] "" VCMS

CM_ BO_ 804 "VCMS VCMS_03_100ms_4";
BO_ 806 BMS_06_100ms_1: 8 BMS
 SG_ DATA : 0|64@1+ (1,0) [0|0] "" BMS

CM_ BO_ 806 "BMS BMS_06_100ms_1";
BO_ 807 BMS_06_100ms_2: 8 BMS
 SG_ DATA : 0|64@1+ (1,0) [0|0] "" BMS

CM_ BO_ 807 "BMS BMS_06_100ms_2";
BO_ 808 BMS_06_100ms_3: 8 BMS
 SG_ DATA : 0|64@1+ (1,0) [0|0] "" BMS

CM_ BO_ 808 "BMS BMS_06_100ms_3";
BO_ 817 BMS_05_100ms_1: 8 BMS
 SG_ DATA : 0|64@1+ (1,0) [0|0] "" BMS

CM_ BO_ 817 "BMS BMS_05_100ms_1";
BO_ 818 BMS_05_100ms_2: 8 BMS
 SG_ DATA : 0|64@1+ (1,0) [0|0] "" BMS

CM_ BO_ 818 "BMS BMS_05_100ms_2";
BO_ 822 BMS_07_100ms_1: 8 BMS
 SG_ DATA : 0|64@1+ (1,0) [0|0] "" BMS

CM_ BO_ 822 "BMS BMS_07_100ms_1";
BO_ 823 BMS_07_100ms_2: 8 BMS
 SG_ DATA : 0|64@1+ (1,0) [0|0] "" BMS

CM_ BO_ 823 "BMS BMS_07_100ms_2";
BO_ 824 BMS_07_100ms_3: 8 BMS
 SG_ DATA : 0|64@1+ (1,0) [0|0] "" BMS

CM_ BO_ 824 "BMS BMS_07_100ms_3";
BO_ 825 BMS_07_100ms_4: 8 BMS
 SG_ DATA : 0|64@1+ (1,0) [0|0] "" BMS

CM_ BO_ 825 "BMS BMS_07_100ms_4";
BO_ 827 CCM_01_100ms_1: 8 CCM
 SG_ DATA : 0|64@1+ (1,0) [0|0] "" CCM

CM_ BO_ 827 "CCM CCM_01_100ms_1";
BO_ 828 CCM_01_100ms_2: 8 CCM
 SG_ DATA : 0|64@1+ (1,0) [0|0] "" CCM

CM_ BO_ 828 "CCM CCM_01_100ms_2";
BO_ 829 CCM_01_100ms_3: 8 CCM
 SG_ DATA : 0|64@1+ (1,0) [0|0] "" CCM

CM_ BO_ 829 "CCM CCM_01_100ms_3";
BO_ 830 CCM_01_100ms_4: 8 CCM
 SG_ DATA : 0|64@1+ (1,0) [0|0] "" CCM

CM_ BO_ 830 "CCM CCM_01_100ms_4";
BO_ 831 ADAS_PRK_RVM_01_600ms: 8 ADAS
 SG_ DATA : 0|64@1+ (1,0) [0|0] "" ADAS

CM_ BO_ 831 "ADAS ADAS_PRK_RVM_01_600ms";
BO_ 849 CCM_02_100ms_1: 8 CCM
 SG_ DATA : 0|64@1+ (1,0) [0|0] "" CCM

CM_ BO_ 849 "CCM CCM_02_100ms_1";
BO_ 850 CCM_02_100ms_2: 8 CCM
 SG_ DATA : 0|64@1+ (1,0) [0|0] "" CCM

CM_ BO_ 850 "CCM CCM_02_100ms_2";
BO_ 851 CCM_02_100ms_3: 8 CCM
 SG_ DATA : 0|64@1+ (1,0) [0|0] "" CCM

CM_ BO_ 851 "CCM CCM_02_100ms_3";
BO_ 852 CCM_02_100ms_4: 8 CCM
 SG_ DATA : 0|64@1+ (1,0) [0|0] "" CCM

CM_ BO_ 852 "CCM CCM_02_100ms_4";
BO_ 859 AFS_01_100ms: 8 AFS
 SG_ DATA : 0|64@1+ (1,0) [0|0] "" AFS

CM_ BO_ 859 "AFS AFS_01_100ms";
BO_ 865 BMS_03_100ms_1: 8 BMS
 SG_ DATA : 0|64@1+ (1,0) [0|0] "" BMS

CM_ BO_ 865 "BMS BMS_03_100ms_1";
BO_ 866 BMS_03_100ms_2: 8 BMS
 SG_ DATA : 0|64@1+ (1,0) [0|0] "" BMS

CM_ BO_ 866 "BMS BMS_03_100ms_2";
BO_ 867 BMS_03_100ms_3: 8 BMS
 SG_ DATA : 0|64@1+ (1,0) [0|0] "" BMS

CM_ BO_ 867 "BMS BMS_03_100ms_3";
BO_ 868 BMS_03_100ms_4: 8 BMS
 SG_ DATA : 0|64@1+ (1,0) [0|0] "" BMS

CM_ BO_ 868 "BMS BMS_03_100ms_4";
BO_ 870 BMS_09_100ms_1: 8 BMS
 SG_ DATA : 0|64@1+ (1,0) [0|0] "" BMS

CM_ BO_ 870 "BMS BMS_09_100ms_1";
BO_ 871 BMS_09_100ms_2: 8 BMS
 SG_ DATA : 0|64@1+ (1,0) [0|0] "" BMS

CM_ BO_ 871 "BMS BMS_09_100ms_2";
BO_ 872 BMS_09_100ms_3: 8 BMS
 SG_ DATA : 0|64@1+ (1,0) [0|0] "" BMS

CM_ BO_ 872 "BMS BMS_09_100ms_3";
BO_ 873 BMS_09_100ms_4: 8 BMS
 SG_ DATA : 0|64@1+ (1,0) [0|0] "" BMS

CM_ BO_ 873 "BMS BMS_09_100ms_4";
BO_ 897 DATC_04_200ms: 8 DATC
 SG_ DATA : 0|64@1+ (1,0) [0|0] "" DATC

CM_ BO_ 897 "DATC DATC_04_200ms";
BO_ 898 DATC_05_200ms: 8 DATC
 SG_ DATA : 0|64@1+ (1,0) [0|0] "" DATC

CM_ BO_ 898 "DATC DATC_05_200ms";
BO_ 899 DATC_06_200ms: 8 DATC
 SG_ DATA : 0|64@1+ (1,0) [0|0] "" DATC

CM_ BO_ 899 "DATC DATC_06_200ms";
BO_ 900 DATC_07_200ms: 8 DATC
 SG_ DATA : 0|64@1+ (1,0) [0|0] "" DATC

CM_ BO_ 900 "DATC DATC_07_200ms";
BO_ 907 CLU_03_200ms_1: 8 CLU
 SG_ DATA : 0|64@1+ (1,0) [0|0] "" CLU

CM_ BO_ 907 "CLU CLU_03_200ms_1";
BO_ 908 CLU_03_200ms_2: 8 CLU
 SG_ DATA : 0|64@1+ (1,0) [0|0] "" CLU

CM_ BO_ 908 "CLU CLU_03_200ms_2";
BO_ 918 MCU_04_200ms_1: 8 MCU
 SG_ DATA : 0|64@1+ (1,0) [0|0] "" MCU

CM_ BO_ 918 "MCU MCU_04_200ms_1";
BO_ 919 MCU_04_200ms_2: 8 MCU
 SG_ DATA : 0|64@1+ (1,0) [0|0] "" MCU

CM_ BO_ 919 "MCU MCU_04_200ms_2";
BO_ 920 MCU_04_200ms_3: 8 MCU
 SG_ DATA : 0|64@1+ (1,0) [0|0] "" MCU

CM_ BO_ 920 "MCU MCU_04_200ms_3";
BO_ 923 TMU_01_200ms: 8 TMU
 SG_ Session_State : 0|8@1+ (1,0) [0|255] "" TMU
 SG_ Setpoint_Raw : 8|8@1+ (0.5,14) [14|32] "C" TMU
 SG_ Session_Counter : 24|8@1+ (1,0) [0|63] "" TMU
 SG_ Command_Class : 40|8@1+ (1,0) [0|255] "" TMU
 SG_ Session_Phase : 48|8@1+ (1,0) [0|255] "" TMU

CM_ BO_ 923 "TMU_01_200ms (0x39B) - the telematics side of a remote climate / lock / charge session. Seen on I-CAN only, never on M-CAN. Idle traffic is 00 00 00 00 00 03 10 00; a live session is 50 <setpoint> 00 <counter> 00 03 10 00 at 5 Hz, and the 00 03 10 00 tail clears to zeros ~8.3 s in. Byte 1 (D2) is the climate setpoint (0x06=17.0, 0x10=22.0, 0x11=22.5, 0x12=23.0 C) and it LEADS the matching code in 0x2AC byte 4 (~0.5 s) and 0x380 bytes 3-6 (~1.7 s) in all four 2026-11-03 captures, so the HVAC reports what this frame announces.";
CM_ SG_ 923 Setpoint_Raw "byte 1 (D2): raw setpoint, 0x06=17.0 C, 0x10=22.0 C, 0x16=25.0 C. 0x00 = no setpoint announced (idle).";
CM_ SG_ 923 Session_Counter "byte 3 (D4): seen stepping +0x04 and wrapping at 0x40 (16 values over 3 s at 5 Hz); one 0x01 was seen at a session start, so the step rule is not fully understood.";
CM_ SG_ 923 Command_Class "byte 5 (D6): 0x01 lock/unlock, 0x02 charge limit, 0x03 climate. Not settled: a cloud climate start used 0x01.";
CM_ SG_ 923 Session_Phase "byte 6 (D7): 0x10 normally, 0x14 in the climate closing frame (40 06 00 18 00 03 14 00).";

VAL_ 923 Session_State 0 "Pending_or_Idle" 64 "Closing" 80 "Running" ;
VAL_ 923 Command_Class 1 "Lock_Unlock" 2 "Charge_Limit" 3 "Climate" ;
BO_ 929 TPMS_01_200ms_1: 8 TPMS
 SG_ DATA : 0|64@1+ (1,0) [0|0] "" TPMS

CM_ BO_ 929 "TPMS TPMS_01_200ms_1";
BO_ 930 TPMS_01_200ms_2: 8 TPMS
 SG_ DATA : 0|64@1+ (1,0) [0|0] "" TPMS

CM_ BO_ 930 "TPMS TPMS_01_200ms_2";
BO_ 934 PTGM_01_200ms: 8 PTGM
 SG_ DATA : 0|64@1+ (1,0) [0|0] "" PTGM

CM_ BO_ 934 "PTGM PTGM_01_200ms";
BO_ 936 SVM_05_600ms: 8 SVM
 SG_ DATA : 0|64@1+ (1,0) [0|0] "" SVM

CM_ BO_ 936 "SVM SVM_05_600ms";
BO_ 945 DATC_09_200ms: 8 DATC
 SG_ DATA : 0|64@1+ (1,0) [0|0] "" DATC

CM_ BO_ 945 "DATC DATC_09_200ms";
BO_ 950 OBC_02_200ms_1: 8 OBC
 SG_ DATA : 0|64@1+ (1,0) [0|0] "" OBC

CM_ BO_ 950 "OBC OBC_02_200ms_1";
BO_ 951 OBC_02_200ms_2: 8 OBC
 SG_ DATA : 0|64@1+ (1,0) [0|0] "" OBC

CM_ BO_ 951 "OBC OBC_02_200ms_2";
BO_ 952 OBC_02_200ms_3: 8 OBC
 SG_ DATA : 0|64@1+ (1,0) [0|0] "" OBC

CM_ BO_ 952 "OBC OBC_02_200ms_3";
BO_ 953 OBC_02_200ms_4: 8 OBC
 SG_ DATA : 0|64@1+ (1,0) [0|0] "" OBC

CM_ BO_ 953 "OBC OBC_02_200ms_4";
BO_ 955 BMS_11_10ms_1: 8 BMS
 SG_ DATA : 0|64@1+ (1,0) [0|0] "" BMS

CM_ BO_ 955 "BMS BMS_11_10ms_1";
BO_ 956 BMS_11_10ms_2: 8 BMS
 SG_ DATA : 0|64@1+ (1,0) [0|0] "" BMS

CM_ BO_ 956 "BMS BMS_11_10ms_2";
BO_ 957 BMS_11_10ms_3: 8 BMS
 SG_ DATA : 0|64@1+ (1,0) [0|0] "" BMS

CM_ BO_ 957 "BMS BMS_11_10ms_3";
BO_ 958 BMS_11_10ms_4: 8 BMS
 SG_ DATA : 0|64@1+ (1,0) [0|0] "" BMS

CM_ BO_ 958 "BMS BMS_11_10ms_4";
BO_ 961 MFSW_01_200ms: 8 MFSW
 SG_ DATA : 0|64@1+ (1,0) [0|0] "" MFSW

CM_ BO_ 961 "MFSW MFSW_01_200ms";
BO_ 962 MFSW_02_200ms: 8 MFSW
 SG_ DATA : 0|64@1+ (1,0) [0|0] "" MFSW

CM_ BO_ 962 "MFSW MFSW_02_200ms";
BO_ 978 BMS_25_500ms_1: 8 BMS
 SG_ DATA : 0|64@1+ (1,0) [0|0] "" BMS

CM_ BO_ 978 "BMS BMS_25_500ms_1";
BO_ 979 BMS_25_500ms_2: 8 BMS
 SG_ DATA : 0|64@1+ (1,0) [0|0] "" BMS

CM_ BO_ 979 "BMS BMS_25_500ms_2";
BO_ 980 BMS_25_500ms_3: 8 BMS
 SG_ DATA : 0|64@1+ (1,0) [0|0] "" BMS

CM_ BO_ 980 "BMS BMS_25_500ms_3";
BO_ 981 BMS_25_500ms_4: 8 BMS
 SG_ DATA : 0|64@1+ (1,0) [0|0] "" BMS

CM_ BO_ 981 "BMS BMS_25_500ms_4";
BO_ 1002 DVRS_HU_PE_00: 8 DVRS
 SG_ DATA : 0|64@1+ (1,0) [0|0] "" DVRS

CM_ BO_ 1002 "DVRS DVRS_HU_PE_00";
BO_ 1014 BMS_12_1000ms_1: 8 BMS
 SG_ DATA : 0|64@1+ (1,0) [0|0] "" BMS

CM_ BO_ 1014 "BMS BMS_12_1000ms_1";
BO_ 1015 BMS_12_1000ms_2: 8 BMS
 SG_ DATA : 0|64@1+ (1,0) [0|0] "" BMS

CM_ BO_ 1015 "BMS BMS_12_1000ms_2";
BO_ 1016 BMS_12_1000ms_3: 8 BMS
 SG_ DATA : 0|64@1+ (1,0) [0|0] "" BMS

CM_ BO_ 1016 "BMS BMS_12_1000ms_3";
BO_ 1017 BMS_12_1000ms_4: 8 BMS
 SG_ DATA : 0|64@1+ (1,0) [0|0] "" BMS

CM_ BO_ 1017 "BMS BMS_12_1000ms_4";
BO_ 1031 APSM_02_200ms: 8 APSM
 SG_ DATA : 0|64@1+ (1,0) [0|0] "" APSM

CM_ BO_ 1031 "APSM APSM_02_200ms";
BO_ 1040 ICU_10_200ms: 8 ICU
 SG_ DATA : 0|64@1+ (1,0) [0|0] "" ICU

CM_ BO_ 1040 "ICU ICU_10_200ms";
BO_ 1043 ICU_04_200ms: 8 ICU
 SG_ DATA : 0|64@1+ (1,0) [0|0] "" ICU

CM_ BO_ 1043 "ICU ICU_04_200ms";
BO_ 1045 RVM_01_600ms: 8 RVM
 SG_ DATA : 0|64@1+ (1,0) [0|0] "" RVM

CM_ BO_ 1045 "RVM RVM_01_600ms";
BO_ 1046 ICU_06_200ms: 8 ICU
 SG_ DATA : 0|64@1+ (1,0) [0|0] "" ICU

CM_ BO_ 1046 "ICU ICU_06_200ms";
BO_ 1047 ICU_07_200ms: 8 ICU
 SG_ DATA : 0|64@1+ (1,0) [0|0] "" ICU

CM_ BO_ 1047 "ICU ICU_07_200ms";
BO_ 1049 ICU_09_200ms: 8 ICU
 SG_ DATA : 0|64@1+ (1,0) [0|0] "" ICU

CM_ BO_ 1049 "ICU ICU_09_200ms";
BO_ 1050 BCM_07_200ms: 8 BCM
 SG_ DATA : 0|64@1+ (1,0) [0|0] "" BCM

CM_ BO_ 1050 "BCM BCM_07_200ms";
BO_ 1051 BCM_08_200ms: 8 BCM
 SG_ DATA : 0|64@1+ (1,0) [0|0] "" BCM

CM_ BO_ 1051 "BCM BCM_08_200ms";
BO_ 1052 BCM_09_200ms: 8 BCM
 SG_ DATA : 0|64@1+ (1,0) [0|0] "" BCM

CM_ BO_ 1052 "BCM BCM_09_200ms";
BO_ 1058 BCM_10_200ms: 8 BCM
 SG_ DATA : 0|64@1+ (1,0) [0|0] "" BCM

CM_ BO_ 1058 "BCM BCM_10_200ms";
BO_ 1065 DATC_12_200ms: 8 DATC
 SG_ DATA : 0|64@1+ (1,0) [0|0] "" DATC

CM_ BO_ 1065 "DATC DATC_12_200ms";
BO_ 1067 SCM_01_200ms: 8 SCM
 SG_ DATA : 0|64@1+ (1,0) [0|0] "" SCM

CM_ BO_ 1067 "SCM SCM_01_200ms";
BO_ 1074 BCM_11_200ms: 8 BCM
 SG_ DATA : 0|64@1+ (1,0) [0|0] "" BCM

CM_ BO_ 1074 "BCM BCM_11_200ms";
BO_ 1076 IAU_16_200ms: 8 IAU
 SG_ DATA : 0|64@1+ (1,0) [0|0] "" IAU

CM_ BO_ 1076 "IAU IAU_16_200ms";
BO_ 1090 BCM_12_200ms: 8 BCM
 SG_ DATA : 0|64@1+ (1,0) [0|0] "" BCM

CM_ BO_ 1090 "BCM BCM_12_200ms";
BO_ 1135 CLU_13_00ms: 8 CLU
 SG_ DATA : 0|64@1+ (1,0) [0|0] "" CLU

CM_ BO_ 1135 "CLU CLU_13_00ms";
BO_ 1143 SVM_02_600ms: 8 SVM
 SG_ DATA : 0|64@1+ (1,0) [0|0] "" SVM

CM_ BO_ 1143 "SVM SVM_02_600ms";
BO_ 1145 CLU_12_00ms: 8 CLU
 SG_ DATA : 0|64@1+ (1,0) [0|0] "" CLU

CM_ BO_ 1145 "CLU CLU_12_00ms";
BO_ 1153 MCU_05_1000ms_1: 8 MCU
 SG_ DATA : 0|64@1+ (1,0) [0|0] "" MCU

CM_ BO_ 1153 "MCU MCU_05_1000ms_1";
BO_ 1154 MCU_05_1000ms_2: 8 MCU
 SG_ DATA : 0|64@1+ (1,0) [0|0] "" MCU

CM_ BO_ 1154 "MCU MCU_05_1000ms_2";
BO_ 1155 MCU_05_1000ms_3: 8 MCU
 SG_ DATA : 0|64@1+ (1,0) [0|0] "" MCU

CM_ BO_ 1155 "MCU MCU_05_1000ms_3";
BO_ 1156 MCU_05_1000ms_4: 8 MCU
 SG_ DATA : 0|64@1+ (1,0) [0|0] "" MCU

CM_ BO_ 1156 "MCU MCU_05_1000ms_4";
BO_ 1161 IBU_MFSW_02_200ms: 8 IBU
 SG_ DATA : 0|64@1+ (1,0) [0|0] "" IBU

CM_ BO_ 1161 "IBU IBU_MFSW_02_200ms";
BO_ 1163 ODS_01_1000ms_1: 8 ODS
 SG_ DATA : 0|64@1+ (1,0) [0|0] "" ODS

CM_ BO_ 1163 "ODS ODS_01_1000ms_1";
BO_ 1164 ODS_01_1000ms_2: 8 ODS
 SG_ DATA : 0|64@1+ (1,0) [0|0] "" ODS

CM_ BO_ 1164 "ODS ODS_01_1000ms_2";
BO_ 1167 ICU_11_1000ms: 8 ICU
 SG_ DATA : 0|64@1+ (1,0) [0|0] "" ICU

CM_ BO_ 1167 "ICU ICU_11_1000ms";
BO_ 1180 FR_SHVU_02_00ms: 8 FR
 SG_ DATA : 0|64@1+ (1,0) [0|0] "" FR

CM_ BO_ 1180 "FR FR_SHVU_02_00ms";
BO_ 1227 PSM_01_00ms: 8 PSM
 SG_ DATA : 0|64@1+ (1,0) [0|0] "" PSM

CM_ BO_ 1227 "PSM PSM_01_00ms";
BO_ 1231 IFS_01_200ms: 8 IFS
 SG_ DATA : 0|64@1+ (1,0) [0|0] "" IFS

CM_ BO_ 1231 "IFS IFS_01_200ms";
BO_ 1235 CLU_07_00ms: 8 CLU
 SG_ DATA : 0|64@1+ (1,0) [0|0] "" CLU

CM_ BO_ 1235 "CLU CLU_07_00ms";
BO_ 1236 CLU_08_00ms: 8 CLU
 SG_ DATA : 0|64@1+ (1,0) [0|0] "" CLU

CM_ BO_ 1236 "CLU CLU_08_00ms";
BO_ 1242 CLU_09_00ms: 8 CLU
 SG_ DATA : 0|64@1+ (1,0) [0|0] "" CLU

CM_ BO_ 1242 "CLU CLU_09_00ms";
BO_ 1251 IAU_13_00ms: 8 IAU
 SG_ DATA : 0|64@1+ (1,0) [0|0] "" IAU

CM_ BO_ 1251 "IAU IAU_13_00ms";
BO_ 1548 AMP_HU_PE_01: 8 AMP
 SG_ DATA : 0|64@1+ (1,0) [0|0] "" AMP

CM_ BO_ 1548 "AMP AMP_HU_PE_01";
BO_ 1549 AMP_HU_PE_02: 8 AMP
 SG_ DATA : 0|64@1+ (1,0) [0|0] "" AMP

CM_ BO_ 1549 "AMP AMP_HU_PE_02";
BO_ 1550 AMP_HU_PE_03: 8 AMP
 SG_ DATA : 0|64@1+ (1,0) [0|0] "" AMP

CM_ BO_ 1550 "AMP AMP_HU_PE_03";
BO_ 1551 AMP_HU_PE_04: 8 AMP
 SG_ DATA : 0|64@1+ (1,0) [0|0] "" AMP

CM_ BO_ 1551 "AMP AMP_HU_PE_04";

BA_DEF_ BO_ "GenMsgCycleTime" INT 0 10000;
BA_DEF_DEF_ "GenMsgCycleTime" 0;
VAL_TABLE_ GenMsgCycleTime 0 "Event/On-change" 1 "1 ms" 2 "2 ms" 10 "10 ms" 20 "20 ms" 40 "40 ms" 50 "50 ms" 100 "100 ms" 200 "200 ms" 500 "500 ms" 600 "600 ms" 1000 "1000 ms";
BA_ "GenMsgCycleTime" BO_ 54 10;
BA_ "GenMsgCycleTime" BO_ 55 10;
BA_ "GenMsgCycleTime" BO_ 56 10;
BA_ "GenMsgCycleTime" BO_ 57 10;
BA_ "GenMsgCycleTime" BO_ 75 10;
BA_ "GenMsgCycleTime" BO_ 76 10;
BA_ "GenMsgCycleTime" BO_ 77 10;
BA_ "GenMsgCycleTime" BO_ 78 10;
BA_ "GenMsgCycleTime" BO_ 86 500;
BA_ "GenMsgCycleTime" BO_ 87 500;
BA_ "GenMsgCycleTime" BO_ 88 500;
BA_ "GenMsgCycleTime" BO_ 89 500;
BA_ "GenMsgCycleTime" BO_ 97 10;
BA_ "GenMsgCycleTime" BO_ 98 10;
BA_ "GenMsgCycleTime" BO_ 99 10;
BA_ "GenMsgCycleTime" BO_ 100 10;
BA_ "GenMsgCycleTime" BO_ 102 10;
BA_ "GenMsgCycleTime" BO_ 103 10;
BA_ "GenMsgCycleTime" BO_ 104 10;
BA_ "GenMsgCycleTime" BO_ 105 10;
BA_ "GenMsgCycleTime" BO_ 111 10;
BA_ "GenMsgCycleTime" BO_ 145 100;
BA_ "GenMsgCycleTime" BO_ 146 100;
BA_ "GenMsgCycleTime" BO_ 147 100;
BA_ "GenMsgCycleTime" BO_ 148 100;
BA_ "GenMsgCycleTime" BO_ 161 10;
BA_ "GenMsgCycleTime" BO_ 162 10;
BA_ "GenMsgCycleTime" BO_ 163 10;
BA_ "GenMsgCycleTime" BO_ 210 200;
BA_ "GenMsgCycleTime" BO_ 230 10;
BA_ "GenMsgCycleTime" BO_ 231 10;
BA_ "GenMsgCycleTime" BO_ 232 10;
BA_ "GenMsgCycleTime" BO_ 233 10;
BA_ "GenMsgCycleTime" BO_ 235 10;
BA_ "GenMsgCycleTime" BO_ 236 10;
BA_ "GenMsgCycleTime" BO_ 237 10;
BA_ "GenMsgCycleTime" BO_ 246 10;
BA_ "GenMsgCycleTime" BO_ 247 10;
BA_ "GenMsgCycleTime" BO_ 248 10;
BA_ "GenMsgCycleTime" BO_ 249 10;
BA_ "GenMsgCycleTime" BO_ 267 10;
BA_ "GenMsgCycleTime" BO_ 268 10;
BA_ "GenMsgCycleTime" BO_ 269 10;
BA_ "GenMsgCycleTime" BO_ 270 10;
BA_ "GenMsgCycleTime" BO_ 283 10;
BA_ "GenMsgCycleTime" BO_ 284 10;
BA_ "GenMsgCycleTime" BO_ 289 10;
BA_ "GenMsgCycleTime" BO_ 290 10;
BA_ "GenMsgCycleTime" BO_ 291 10;
BA_ "GenMsgCycleTime" BO_ 292 10;
BA_ "GenMsgCycleTime" BO_ 294 10;
BA_ "GenMsgCycleTime" BO_ 295 10;
BA_ "GenMsgCycleTime" BO_ 299 10;
BA_ "GenMsgCycleTime" BO_ 300 10;
BA_ "GenMsgCycleTime" BO_ 310 10;
BA_ "GenMsgCycleTime" BO_ 311 10;
BA_ "GenMsgCycleTime" BO_ 320 10;
BA_ "GenMsgCycleTime" BO_ 326 20;
BA_ "GenMsgCycleTime" BO_ 327 20;
BA_ "GenMsgCycleTime" BO_ 328 20;
BA_ "GenMsgCycleTime" BO_ 329 20;
BA_ "GenMsgCycleTime" BO_ 337 100;
BA_ "GenMsgCycleTime" BO_ 338 100;
BA_ "GenMsgCycleTime" BO_ 339 100;
BA_ "GenMsgCycleTime" BO_ 340 100;
BA_ "GenMsgCycleTime" BO_ 342 10;
BA_ "GenMsgCycleTime" BO_ 343 10;
BA_ "GenMsgCycleTime" BO_ 353 20;
BA_ "GenMsgCycleTime" BO_ 354 20;
BA_ "GenMsgCycleTime" BO_ 358 20;
BA_ "GenMsgCycleTime" BO_ 359 20;
BA_ "GenMsgCycleTime" BO_ 360 20;
BA_ "GenMsgCycleTime" BO_ 363 20;
BA_ "GenMsgCycleTime" BO_ 364 20;
BA_ "GenMsgCycleTime" BO_ 365 20;
BA_ "GenMsgCycleTime" BO_ 366 20;
BA_ "GenMsgCycleTime" BO_ 369 20;
BA_ "GenMsgCycleTime" BO_ 370 20;
BA_ "GenMsgCycleTime" BO_ 374 20;
BA_ "GenMsgCycleTime" BO_ 375 20;
BA_ "GenMsgCycleTime" BO_ 376 20;
BA_ "GenMsgCycleTime" BO_ 384 20;
BA_ "GenMsgCycleTime" BO_ 389 20;
BA_ "GenMsgCycleTime" BO_ 395 20;
BA_ "GenMsgCycleTime" BO_ 396 20;
BA_ "GenMsgCycleTime" BO_ 397 20;
BA_ "GenMsgCycleTime" BO_ 398 20;
BA_ "GenMsgCycleTime" BO_ 406 10;
BA_ "GenMsgCycleTime" BO_ 407 10;
BA_ "GenMsgCycleTime" BO_ 408 10;
BA_ "GenMsgCycleTime" BO_ 409 10;
BA_ "GenMsgCycleTime" BO_ 411 10;
BA_ "GenMsgCycleTime" BO_ 412 10;
BA_ "GenMsgCycleTime" BO_ 413 10;
BA_ "GenMsgCycleTime" BO_ 414 10;
BA_ "GenMsgCycleTime" BO_ 417 20;
BA_ "GenMsgCycleTime" BO_ 418 20;
BA_ "GenMsgCycleTime" BO_ 419 20;
BA_ "GenMsgCycleTime" BO_ 420 20;
BA_ "GenMsgCycleTime" BO_ 427 20;
BA_ "GenMsgCycleTime" BO_ 428 20;
BA_ "GenMsgCycleTime" BO_ 433 20;
BA_ "GenMsgCycleTime" BO_ 434 20;
BA_ "GenMsgCycleTime" BO_ 435 20;
BA_ "GenMsgCycleTime" BO_ 436 20;
BA_ "GenMsgCycleTime" BO_ 438 50;
BA_ "GenMsgCycleTime" BO_ 439 50;
BA_ "GenMsgCycleTime" BO_ 440 50;
BA_ "GenMsgCycleTime" BO_ 441 50;
BA_ "GenMsgCycleTime" BO_ 443 50;
BA_ "GenMsgCycleTime" BO_ 444 50;
BA_ "GenMsgCycleTime" BO_ 445 50;
BA_ "GenMsgCycleTime" BO_ 481 50;
BA_ "GenMsgCycleTime" BO_ 482 50;
BA_ "GenMsgCycleTime" BO_ 486 50;
BA_ "GenMsgCycleTime" BO_ 487 50;
BA_ "GenMsgCycleTime" BO_ 491 50;
BA_ "GenMsgCycleTime" BO_ 492 50;
BA_ "GenMsgCycleTime" BO_ 493 50;
BA_ "GenMsgCycleTime" BO_ 494 50;
BA_ "GenMsgCycleTime" BO_ 497 50;
BA_ "GenMsgCycleTime" BO_ 502 100;
BA_ "GenMsgCycleTime" BO_ 503 100;
BA_ "GenMsgCycleTime" BO_ 504 100;
BA_ "GenMsgCycleTime" BO_ 505 100;
BA_ "GenMsgCycleTime" BO_ 507 100;
BA_ "GenMsgCycleTime" BO_ 508 100;
BA_ "GenMsgCycleTime" BO_ 509 100;
BA_ "GenMsgCycleTime" BO_ 510 100;
BA_ "GenMsgCycleTime" BO_ 512 50;
BA_ "GenMsgCycleTime" BO_ 518 100;
BA_ "GenMsgCycleTime" BO_ 519 100;
BA_ "GenMsgCycleTime" BO_ 520 100;
BA_ "GenMsgCycleTime" BO_ 523 100;
BA_ "GenMsgCycleTime" BO_ 524 100;
BA_ "GenMsgCycleTime" BO_ 550 100;
BA_ "GenMsgCycleTime" BO_ 551 100;
BA_ "GenMsgCycleTime" BO_ 566 100;
BA_ "GenMsgCycleTime" BO_ 567 100;
BA_ "GenMsgCycleTime" BO_ 568 100;
BA_ "GenMsgCycleTime" BO_ 569 100;
BA_ "GenMsgCycleTime" BO_ 582 500;
BA_ "GenMsgCycleTime" BO_ 583 500;
BA_ "GenMsgCycleTime" BO_ 584 500;
BA_ "GenMsgCycleTime" BO_ 585 500;
BA_ "GenMsgCycleTime" BO_ 593 100;
BA_ "GenMsgCycleTime" BO_ 594 100;
BA_ "GenMsgCycleTime" BO_ 595 100;
BA_ "GenMsgCycleTime" BO_ 598 100;
BA_ "GenMsgCycleTime" BO_ 599 100;
BA_ "GenMsgCycleTime" BO_ 600 100;
BA_ "GenMsgCycleTime" BO_ 601 100;
BA_ "GenMsgCycleTime" BO_ 603 100;
BA_ "GenMsgCycleTime" BO_ 604 100;
BA_ "GenMsgCycleTime" BO_ 605 100;
BA_ "GenMsgCycleTime" BO_ 606 100;
BA_ "GenMsgCycleTime" BO_ 630 500;
BA_ "GenMsgCycleTime" BO_ 631 500;
BA_ "GenMsgCycleTime" BO_ 632 500;
BA_ "GenMsgCycleTime" BO_ 633 500;
BA_ "GenMsgCycleTime" BO_ 683 100;
BA_ "GenMsgCycleTime" BO_ 684 100;
BA_ "GenMsgCycleTime" BO_ 685 100;
BA_ "GenMsgCycleTime" BO_ 686 100;
BA_ "GenMsgCycleTime" BO_ 694 100;
BA_ "GenMsgCycleTime" BO_ 695 100;
BA_ "GenMsgCycleTime" BO_ 696 100;
BA_ "GenMsgCycleTime" BO_ 697 100;
BA_ "GenMsgCycleTime" BO_ 699 40;
BA_ "GenMsgCycleTime" BO_ 700 40;
BA_ "GenMsgCycleTime" BO_ 701 40;
BA_ "GenMsgCycleTime" BO_ 702 40;
BA_ "GenMsgCycleTime" BO_ 726 200;
BA_ "GenMsgCycleTime" BO_ 727 200;
BA_ "GenMsgCycleTime" BO_ 728 200;
BA_ "GenMsgCycleTime" BO_ 729 200;
BA_ "GenMsgCycleTime" BO_ 737 100;
BA_ "GenMsgCycleTime" BO_ 738 100;
BA_ "GenMsgCycleTime" BO_ 739 100;
BA_ "GenMsgCycleTime" BO_ 740 100;
BA_ "GenMsgCycleTime" BO_ 742 100;
BA_ "GenMsgCycleTime" BO_ 743 100;
BA_ "GenMsgCycleTime" BO_ 744 100;
BA_ "GenMsgCycleTime" BO_ 745 100;
BA_ "GenMsgCycleTime" BO_ 763 100;
BA_ "GenMsgCycleTime" BO_ 764 100;
BA_ "GenMsgCycleTime" BO_ 765 100;
BA_ "GenMsgCycleTime" BO_ 766 100;
BA_ "GenMsgCycleTime" BO_ 774 1000;
BA_ "GenMsgCycleTime" BO_ 775 1000;
BA_ "GenMsgCycleTime" BO_ 776 1000;
BA_ "GenMsgCycleTime" BO_ 777 1000;
BA_ "GenMsgCycleTime" BO_ 779 100;
BA_ "GenMsgCycleTime" BO_ 780 100;
BA_ "GenMsgCycleTime" BO_ 781 100;
BA_ "GenMsgCycleTime" BO_ 782 100;
BA_ "GenMsgCycleTime" BO_ 795 1000;
BA_ "GenMsgCycleTime" BO_ 796 1000;
BA_ "GenMsgCycleTime" BO_ 797 1000;
BA_ "GenMsgCycleTime" BO_ 798 1000;
BA_ "GenMsgCycleTime" BO_ 801 100;
BA_ "GenMsgCycleTime" BO_ 802 100;
BA_ "GenMsgCycleTime" BO_ 803 100;
BA_ "GenMsgCycleTime" BO_ 804 100;
BA_ "GenMsgCycleTime" BO_ 806 100;
BA_ "GenMsgCycleTime" BO_ 807 100;
BA_ "GenMsgCycleTime" BO_ 808 100;
BA_ "GenMsgCycleTime" BO_ 809 100;
BA_ "GenMsgCycleTime" BO_ 817 100;
BA_ "GenMsgCycleTime" BO_ 818 100;
BA_ "GenMsgCycleTime" BO_ 819 100;
BA_ "GenMsgCycleTime" BO_ 820 100;
BA_ "GenMsgCycleTime" BO_ 822 100;
BA_ "GenMsgCycleTime" BO_ 823 100;
BA_ "GenMsgCycleTime" BO_ 824 100;
BA_ "GenMsgCycleTime" BO_ 825 100;
BA_ "GenMsgCycleTime" BO_ 827 100;
BA_ "GenMsgCycleTime" BO_ 828 100;
BA_ "GenMsgCycleTime" BO_ 829 100;
BA_ "GenMsgCycleTime" BO_ 830 100;
BA_ "GenMsgCycleTime" BO_ 831 600;
BA_ "GenMsgCycleTime" BO_ 849 100;
BA_ "GenMsgCycleTime" BO_ 850 100;
BA_ "GenMsgCycleTime" BO_ 851 100;
BA_ "GenMsgCycleTime" BO_ 852 100;
BA_ "GenMsgCycleTime" BO_ 859 100;
BA_ "GenMsgCycleTime" BO_ 865 100;
BA_ "GenMsgCycleTime" BO_ 866 100;
BA_ "GenMsgCycleTime" BO_ 867 100;
BA_ "GenMsgCycleTime" BO_ 868 100;
BA_ "GenMsgCycleTime" BO_ 870 100;
BA_ "GenMsgCycleTime" BO_ 871 100;
BA_ "GenMsgCycleTime" BO_ 872 100;
BA_ "GenMsgCycleTime" BO_ 873 100;
BA_ "GenMsgCycleTime" BO_ 896 200;
BA_ "GenMsgCycleTime" BO_ 897 200;
BA_ "GenMsgCycleTime" BO_ 898 200;
BA_ "GenMsgCycleTime" BO_ 899 200;
BA_ "GenMsgCycleTime" BO_ 900 200;
BA_ "GenMsgCycleTime" BO_ 907 200;
BA_ "GenMsgCycleTime" BO_ 908 200;
BA_ "GenMsgCycleTime" BO_ 918 200;
BA_ "GenMsgCycleTime" BO_ 919 200;
BA_ "GenMsgCycleTime" BO_ 920 200;
BA_ "GenMsgCycleTime" BO_ 923 200;
BA_ "GenMsgCycleTime" BO_ 929 200;
BA_ "GenMsgCycleTime" BO_ 930 200;
BA_ "GenMsgCycleTime" BO_ 934 200;
BA_ "GenMsgCycleTime" BO_ 936 600;
BA_ "GenMsgCycleTime" BO_ 945 200;
BA_ "GenMsgCycleTime" BO_ 950 200;
BA_ "GenMsgCycleTime" BO_ 951 200;
BA_ "GenMsgCycleTime" BO_ 952 200;
BA_ "GenMsgCycleTime" BO_ 953 200;
BA_ "GenMsgCycleTime" BO_ 955 10;
BA_ "GenMsgCycleTime" BO_ 956 10;
BA_ "GenMsgCycleTime" BO_ 957 10;
BA_ "GenMsgCycleTime" BO_ 958 10;
BA_ "GenMsgCycleTime" BO_ 961 200;
BA_ "GenMsgCycleTime" BO_ 962 200;
BA_ "GenMsgCycleTime" BO_ 978 500;
BA_ "GenMsgCycleTime" BO_ 979 500;
BA_ "GenMsgCycleTime" BO_ 980 500;
BA_ "GenMsgCycleTime" BO_ 981 500;
BA_ "GenMsgCycleTime" BO_ 1014 1000;
BA_ "GenMsgCycleTime" BO_ 1015 1000;
BA_ "GenMsgCycleTime" BO_ 1016 1000;
BA_ "GenMsgCycleTime" BO_ 1017 1000;
BA_ "GenMsgCycleTime" BO_ 1031 200;
BA_ "GenMsgCycleTime" BO_ 1040 200;
BA_ "GenMsgCycleTime" BO_ 1041 200;
BA_ "GenMsgCycleTime" BO_ 1042 200;
BA_ "GenMsgCycleTime" BO_ 1043 200;
BA_ "GenMsgCycleTime" BO_ 1045 600;
BA_ "GenMsgCycleTime" BO_ 1046 200;
BA_ "GenMsgCycleTime" BO_ 1047 200;
BA_ "GenMsgCycleTime" BO_ 1048 200;
BA_ "GenMsgCycleTime" BO_ 1049 200;
BA_ "GenMsgCycleTime" BO_ 1050 200;
BA_ "GenMsgCycleTime" BO_ 1051 200;
BA_ "GenMsgCycleTime" BO_ 1052 200;
BA_ "GenMsgCycleTime" BO_ 1058 200;
BA_ "GenMsgCycleTime" BO_ 1065 200;
BA_ "GenMsgCycleTime" BO_ 1067 200;
BA_ "GenMsgCycleTime" BO_ 1074 200;
BA_ "GenMsgCycleTime" BO_ 1076 200;
BA_ "GenMsgCycleTime" BO_ 1090 200;
BA_ "GenMsgCycleTime" BO_ 1143 600;
BA_ "GenMsgCycleTime" BO_ 1153 1000;
BA_ "GenMsgCycleTime" BO_ 1154 1000;
BA_ "GenMsgCycleTime" BO_ 1155 1000;
BA_ "GenMsgCycleTime" BO_ 1156 1000;
BA_ "GenMsgCycleTime" BO_ 1161 200;
BA_ "GenMsgCycleTime" BO_ 1163 1000;
BA_ "GenMsgCycleTime" BO_ 1164 1000;
BA_ "GenMsgCycleTime" BO_ 1167 1000;
BA_ "GenMsgCycleTime" BO_ 1174 200;
BA_ "GenMsgCycleTime" BO_ 1231 200;
